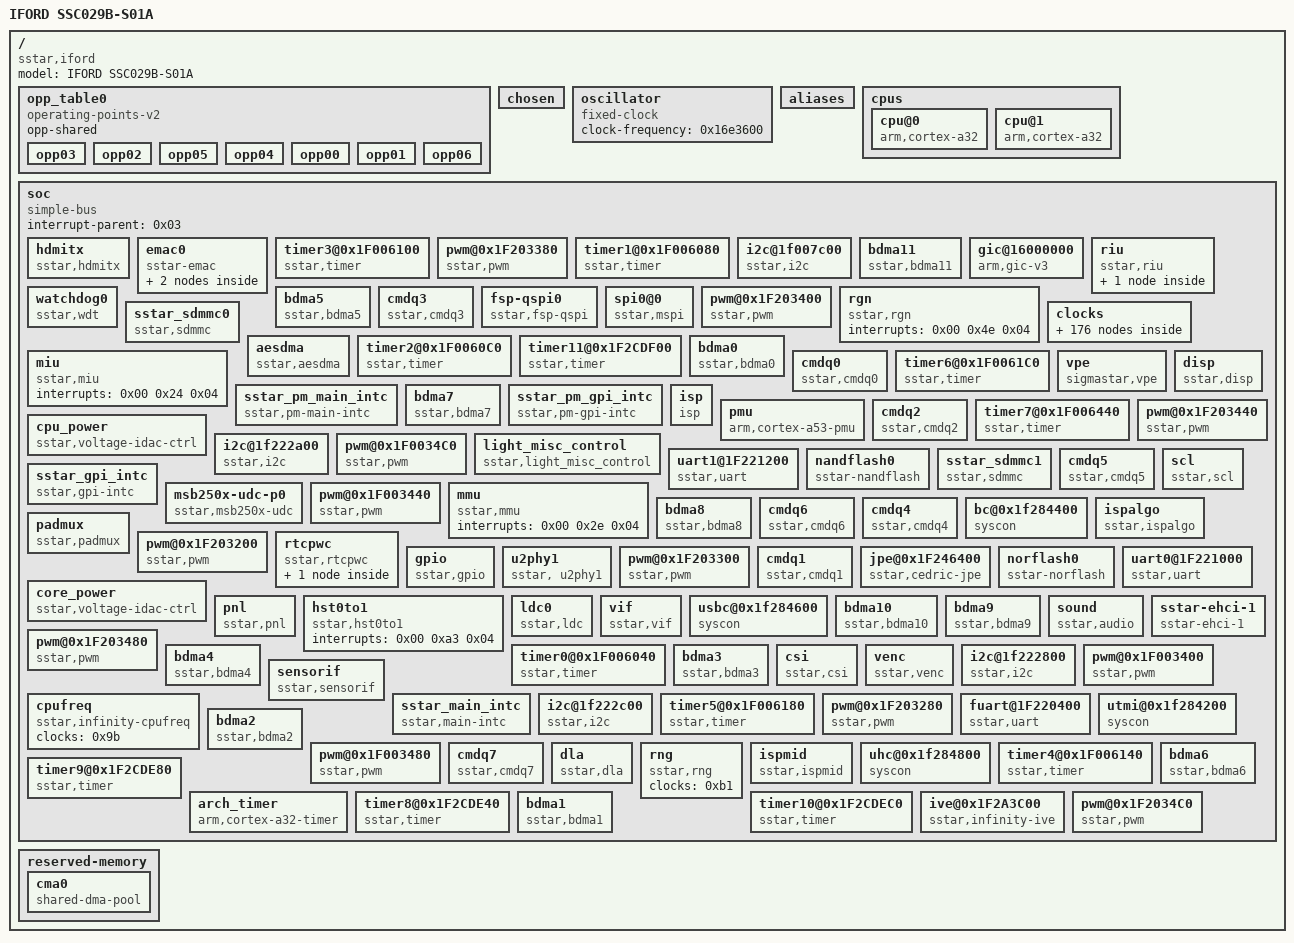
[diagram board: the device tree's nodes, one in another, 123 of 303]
/dts-v1/;

/ {
	model = "IFORD SSC029B-S01A";
	#address-cells = <0x01>;
	#size-cells = <0x01>;
	compatible = "sstar,iford";

	opp_table0 {
		opp-shared;
		phandle = <0x02>;
		compatible = "operating-points-v2";

		opp03 {
			status = "ok";
			opp-hz = <0x00 0x35a4e900>;
			opp-microvolt = <0xd6d80 0xcd140 0xd6d80>;
		};

		opp02 {
			status = "ok";
			opp-hz = <0x00 0x2faf0800>;
			opp-microvolt = <0xcf850 0xc5c10 0xcf850>;
		};

		opp05 {
			status = "ok";
			opp-hz = <0x00 0x4190ab00>;
			opp-microvolt = <0xe30d0 0xde2b0 0xe30d0>;
		};

		opp04 {
			status = "ok";
			opp-hz = <0x00 0x3b9aca00>;
			opp-microvolt = <0xdbba0 0xd4670 0xdbba0>;
		};

		opp00 {
			status = "ok";
			opp-hz = <0x00 0x23c34600>;
			opp-microvolt = <0xc3500 0xbbfd0 0xc3500>;
		};

		opp01 {
			status = "ok";
			opp-hz = <0x00 0x29b92700>;
			opp-microvolt = <0xc8320 0xc0df0 0xc8320>;
		};

		opp06 {
			status = "ok";
			opp-hz = <0x00 0x47868c00>;
			opp-microvolt = <0xecd10 0xe57e0 0xecd10>;
		};
	};

	chosen {
		bootargs = "console=ttyS0,115200n8r root=/dev/mtdblock3 ro init=/linuxrc LX_MEM=0x10000000 mma_heap=mma_heap_name0,miu=0,sz=0x8000000 mma_memblock_remove=1 cma=2M mtdparts=nor0:0x5F000(BOOT),0x1000(ENV),0x300000(KERNEL),0x220000(rootfs),0xB0000(MISC),0x4D0000(miservice),0x500000(customer) nohz=off";
	};

	oscillator {
		#clock-cells = <0x00>;
		phandle = <0xb2>;
		clock-frequency = <0x16e3600>;
		compatible = "fixed-clock";
	};

	__symbols__ {
		CLK_bist_vhe_gp = "/soc/clocks/CLK_bist_vhe_gp";
		CLK_bist_sc_gp = "/soc/clocks/CLK_bist_sc_gp";
		timer11 = "/soc/timer11@0x1F2CDF00";
		jpe0 = "/soc/jpe@0x1F246400";
		CLK_mpll_288m_div2 = "/soc/clocks/CLK_mpll_288m_div2";
		CLK_isp_p = "/soc/clocks/CLK_isp_p";
		CLK_mpll_432m_div16 = "/soc/clocks/CLK_mpll_432m_div16";
		CLK_pm_timer7 = "/soc/clocks/CLK_pm_timer7";
		hdmitx = "/soc/hdmitx";
		emac0 = "/soc/emac0";
		timer0 = "/soc/timer0@0x1F006040";
		CLK_fuart_synth_in = "/soc/clocks/CLK_fuart_synth_in";
		clks = "/soc/clocks";
		CLK_pm_sdio = "/soc/clocks/CLK_pm_sdio";
		CLK_sd = "/soc/clocks/CLK_sd";
		CLK_fclk1 = "/soc/clocks/CLK_fclk1";
		CLK_ipupll_clk = "/soc/clocks/CLK_ipupll_clk";
		CLK_sr02_mclk = "/soc/clocks/CLK_sr02_mclk";
		CLK_pm_high_ext = "/soc/clocks/CLK_pm_high_ext";
		CLK_ven_scdn = "/soc/clocks/CLK_ven_scdn";
		CLK_xtali_sc_gp = "/soc/clocks/CLK_xtali_sc_gp";
		CLK_miic2 = "/soc/clocks/CLK_miic2";
		CLK_riu_w_clk_mcu_if_gp = "/soc/clocks/CLK_riu_w_clk_mcu_if_gp";
		CLK_au_sys_432 = "/soc/clocks/CLK_au_sys_432";
		CLK_pm_timer6 = "/soc/clocks/CLK_pm_timer6";
		usb2phy1_uhc = "/soc/uhc@0x1f284800";
		CLK_xtali = "/soc/clocks/CLK_xtali";
		CLK_wdt = "/soc/clocks/CLK_wdt";
		phy0 = "/soc/emac0/mdio-bus@emac0/ethernet-phy@0";
		CLK_disppll_clk = "/soc/clocks/CLK_disppll_clk";
		timer7 = "/soc/timer7@0x1F006440";
		CLK_bist_ipu_gp = "/soc/clocks/CLK_bist_ipu_gp";
		CLK_pm_pspi0 = "/soc/clocks/CLK_pm_pspi0";
		ive0 = "/soc/ive@0x1F2A3C00";
		CLK_RTC_CLK_32K = "/soc/clocks/CLK_RTC_CLK_32K";
		xtal = "/oscillator";
		CLK_emac_ahb = "/soc/clocks/CLK_emac_ahb";
		rgn = "/soc/rgn";
		CLK_pm_timer5 = "/soc/clocks/CLK_pm_timer5";
		sstar_sdmmc0 = "/soc/sstar_sdmmc0";
		CLK_csi1_mac_top_i = "/soc/clocks/CLK_csi1_mac_top_i";
		CLK_bist = "/soc/clocks/CLK_bist";
		CLK_mpll_123m = "/soc/clocks/CLK_mpll_123m";
		usb2phy1_usbc = "/soc/usbc@0x1f284600";
		timer4 = "/soc/timer4@0x1F006140";
		CLK_source_mux_250m_div8 = "/soc/clocks/CLK_source_mux_250m_div8";
		CLK_riu_w_clk_sc_gp = "/soc/clocks/CLK_riu_w_clk_sc_gp";
		CLK_source_mux_250m_div5 = "/soc/clocks/CLK_source_mux_250m_div5";
		CLK_source_mux_250m = "/soc/clocks/CLK_source_mux_250m";
		CLK_mspi0 = "/soc/clocks/CLK_mspi0";
		CLK_12m_mux_div40 = "/soc/clocks/CLK_12m_mux_div40";
		CLK_fsp_qspi = "/soc/clocks/CLK_fsp_qspi";
		timer6 = "/soc/timer6@0x1F0061C0";
		CLK_pm_fuart1 = "/soc/clocks/CLK_pm_fuart1";
		CLK_VOID = "/soc/clocks/CLK_VOID";
		CLK_pm_uart0 = "/soc/clocks/CLK_pm_uart0";
		CLK_csi0_mac_lptx_top_i = "/soc/clocks/CLK_csi0_mac_lptx_top_i";
		vpe = "/soc/vpe";
		CLK_bist_miu0 = "/soc/clocks/CLK_bist_miu0";
		CLK_ven_sc_if = "/soc/clocks/CLK_ven_sc_if";
		disp = "/soc/disp";
		sstar_pm_main_intc = "/soc/sstar_pm_main_intc";
		CLK_fuart1_synth_in = "/soc/clocks/CLK_fuart1_synth_in";
		pwm0 = "/soc/pwm@0x1F203200";
		timer5 = "/soc/timer5@0x1F006180";
		CLK_pm_sleep = "/soc/clocks/CLK_pm_sleep";
		CLK_fclk1_p = "/soc/clocks/CLK_fclk1_p";
		CLK_fuart_synth_out = "/soc/clocks/CLK_fuart_synth_out";
		CLK_ddr_syn = "/soc/clocks/CLK_ddr_syn";
		CLK_mpll_288m_div4 = "/soc/clocks/CLK_mpll_288m_div4";
		CLK_pm_miic0 = "/soc/clocks/CLK_pm_miic0";
		pwm3 = "/soc/pwm@0x1F203380";
		CLK_riu_w_clk_top = "/soc/clocks/CLK_riu_w_clk_top";
		sstar_pm_gpi_intc = "/soc/sstar_pm_gpi_intc";
		CLK_mpll_432m = "/soc/clocks/CLK_mpll_432m";
		CLK_bist_pm_p = "/soc/clocks/CLK_bist_pm_p";
		CLK_source_mux_250m_div2 = "/soc/clocks/CLK_source_mux_250m_div2";
		isp = "/soc/isp";
		CLK_upll_320m_div16 = "/soc/clocks/CLK_upll_320m_div16";
		CLK_pm_sr_mclk = "/soc/clocks/CLK_pm_sr_mclk";
		pwm5 = "/soc/pwm@0x1F203440";
		CLK_upll_320m_div8 = "/soc/clocks/CLK_upll_320m_div8";
		usb2phy1_utmi = "/soc/utmi@0x1f284200";
		CLK_xtali_12m_div40 = "/soc/clocks/CLK_xtali_12m_div40";
		CLK_ive = "/soc/clocks/CLK_ive";
		CLK_riu_w_clk_mipi_if_gp = "/soc/clocks/CLK_riu_w_clk_mipi_if_gp";
		CLK_mcu_pm = "/soc/clocks/CLK_mcu_pm";
		CLK_disppll_clk_div2 = "/soc/clocks/CLK_disppll_clk_div2";
		CLK_mpll_86m_div16 = "/soc/clocks/CLK_mpll_86m_div16";
		timer8 = "/soc/timer8@0x1F2CDE40";
		CLK_pm_pwm = "/soc/clocks/CLK_pm_pwm";
		CLK_upll_480m = "/soc/clocks/CLK_upll_480m";
		sstar_u2phy1 = "/soc/u2phy1";
		uart1 = "/soc/uart1@1F221200";
		CLK_xtali_12m_div128 = "/soc/clocks/CLK_xtali_12m_div128";
		CLK_mpll_432m_div8 = "/soc/clocks/CLK_mpll_432m_div8";
		CLK_upll_320m_div2 = "/soc/clocks/CLK_upll_320m_div2";
		CLK_xtali_24m = "/soc/clocks/CLK_xtali_24m";
		CLK_xtali_12m_div16 = "/soc/clocks/CLK_xtali_12m_div16";
		CLK_pm_fuart0 = "/soc/clocks/CLK_pm_fuart0";
		CLK_otp = "/soc/clocks/CLK_otp";
		CLK_bist_mcu = "/soc/clocks/CLK_bist_mcu";
		CLK_fclk2_p = "/soc/clocks/CLK_fclk2_p";
		CLK_upll_320m_div10 = "/soc/clocks/CLK_upll_320m_div10";
		CLK_upll_480m_div2 = "/soc/clocks/CLK_upll_480m_div2";
		CLK_spi_synth_pll = "/soc/clocks/CLK_spi_synth_pll";
		sstar_sdmmc1 = "/soc/sstar_sdmmc1";
		CLK_pm_timer4 = "/soc/clocks/CLK_pm_timer4";
		CLK_sr00_mclk = "/soc/clocks/CLK_sr00_mclk";
		sstar_gpi_intc = "/soc/sstar_gpi_intc";
		CLK_ldcfeye = "/soc/clocks/CLK_ldcfeye";
		scl = "/soc/scl";
		CLK_riu_w_clk_in = "/soc/clocks/CLK_riu_w_clk_in";
		CLK_miu_rec = "/soc/clocks/CLK_miu_rec";
		CLK_csi0_ns_top_i = "/soc/clocks/CLK_csi0_ns_top_i";
		CLK_ir = "/soc/clocks/CLK_ir";
		CLK_xtali_12m_div8 = "/soc/clocks/CLK_xtali_12m_div8";
		CLK_aesdma = "/soc/clocks/CLK_aesdma";
		CLK_spi_nonpm = "/soc/clocks/CLK_spi_nonpm";
		CLK_mpll_123m_div2 = "/soc/clocks/CLK_mpll_123m_div2";
		CLK_mcu = "/soc/clocks/CLK_mcu";
		CLK_pwm = "/soc/clocks/CLK_pwm";
		CLK_fuart0_synth_out = "/soc/clocks/CLK_fuart0_synth_out";
		CLK_upll_384m_div2 = "/soc/clocks/CLK_upll_384m_div2";
		ispalgo = "/soc/ispalgo";
		CLK_mpll_86m = "/soc/clocks/CLK_mpll_86m";
		i2c1 = "/soc/i2c@1f222a00";
		CLK_miu_vhe_gp_p = "/soc/clocks/CLK_miu_vhe_gp_p";
		rtcpwc = "/soc/rtcpwc";
		CLK_mspi0_p = "/soc/clocks/CLK_mspi0_p";
		gpio = "/soc/gpio";
		CLK_emac_testrx125_in_lan = "/soc/clocks/CLK_emac_testrx125_in_lan";
		CLK_upll_320m = "/soc/clocks/CLK_upll_320m";
		CLK_CLK_12M_CORE_v_live = "/soc/clocks/CLK_CLK_12M_CORE_v_live";
		CLK_sr03_mclk = "/soc/clocks/CLK_sr03_mclk";
		CLK_fuart = "/soc/clocks/CLK_fuart";
		usb2phy1_bc = "/soc/bc@0x1f284400";
		CLK_mpll_86m_div4 = "/soc/clocks/CLK_mpll_86m_div4";
		CLK_csi0_mac_top_i = "/soc/clocks/CLK_csi0_mac_top_i";
		CLK_miu_isp_gp_p = "/soc/clocks/CLK_miu_isp_gp_p";
		pwm11 = "/soc/pwm@0x1F0034C0";
		CLK_bist_pm = "/soc/clocks/CLK_bist_pm";
		pnl = "/soc/pnl";
		CLK_riu_w_clk_hemcu_gp = "/soc/clocks/CLK_riu_w_clk_hemcu_gp";
		CLK_isp = "/soc/clocks/CLK_isp";
		CLK_rtc = "/soc/clocks/CLK_rtc";
		pwm2 = "/soc/pwm@0x1F203300";
		ldc0 = "/soc/ldc0";
		CLK_vif_pm = "/soc/clocks/CLK_vif_pm";
		i2c3 = "/soc/i2c@1f007c00";
		CLK_fuart0 = "/soc/clocks/CLK_fuart0";
		CLK_miu_sc_gp_p = "/soc/clocks/CLK_miu_sc_gp_p";
		vif = "/soc/vif";
		CLK_mpll_216m = "/soc/clocks/CLK_mpll_216m";
		CLK_pm_riu_w_clk_in = "/soc/clocks/CLK_pm_riu_w_clk_in";
		CLK_pir_pm = "/soc/clocks/CLK_pir_pm";
		i2c2 = "/soc/i2c@1f222c00";
		CLK_fuart1_synth_out = "/soc/clocks/CLK_fuart1_synth_out";
		CLK_ipuff = "/soc/clocks/CLK_ipuff";
		pwm8 = "/soc/pwm@0x1F003400";
		CLK_ipu = "/soc/clocks/CLK_ipu";
		CLK_real_live = "/soc/clocks/CLK_real_live";
		CLK_miu_boot = "/soc/clocks/CLK_miu_boot";
		CLK_cpu_pll = "/soc/clocks/CLK_cpu_pll";
		CLK_csi1_mac_lptx_top_i = "/soc/clocks/CLK_csi1_mac_lptx_top_i";
		timer10 = "/soc/timer10@0x1F2CDEC0";
		pwm4 = "/soc/pwm@0x1F203400";
		CLK_12m_mux = "/soc/clocks/CLK_12m_mux";
		csi = "/soc/csi";
		CLK_sr01_mclk = "/soc/clocks/CLK_sr01_mclk";
		CLK_miic0 = "/soc/clocks/CLK_miic0";
		pwm7 = "/soc/pwm@0x1F2034C0";
		CLK_mpll_288m_div8 = "/soc/clocks/CLK_mpll_288m_div8";
		CLK_upll_960m = "/soc/clocks/CLK_upll_960m";
		CLK_jpe = "/soc/clocks/CLK_jpe";
		CLK_sar = "/soc/clocks/CLK_sar";
		CLK_ssi_dphy = "/soc/clocks/CLK_ssi_dphy";
		sensorif = "/soc/sensorif";
		timer9 = "/soc/timer9@0x1F2CDE80";
		uart0 = "/soc/uart0@1F221000";
		CLK_sr_mclk = "/soc/clocks/CLK_sr_mclk";
		CLK_upll_384m = "/soc/clocks/CLK_upll_384m";
		CLK_ven_axi = "/soc/clocks/CLK_ven_axi";
		sstar_main_intc = "/soc/sstar_main_intc";
		CLK_csi1_ns_top_i = "/soc/clocks/CLK_csi1_ns_top_i";
		CLK_disp_pixel_0 = "/soc/clocks/CLK_disp_pixel_0";
		CLK_upll_48m = "/soc/clocks/CLK_upll_48m";
		CLK_xtali_12m_div64 = "/soc/clocks/CLK_xtali_12m_div64";
		CLK_live = "/soc/clocks/CLK_live";
		i2c0 = "/soc/i2c@1f222800";
		CLK_pad_test = "/soc/clocks/CLK_pad_test";
		CLK_miu_p = "/soc/clocks/CLK_miu_p";
		CLK_armpll_37p125m = "/soc/clocks/CLK_armpll_37p125m";
		CLK_bist_isp_gp = "/soc/clocks/CLK_bist_isp_gp";
		pwm6 = "/soc/pwm@0x1F203480";
		CLK_riubrdg = "/soc/clocks/CLK_riubrdg";
		CLK_hemcu = "/soc/clocks/CLK_hemcu";
		gic = "/soc/gic@16000000";
		CLK_mcu_pm_p = "/soc/clocks/CLK_mcu_pm_p";
		CLK_source_mux_250m_div4 = "/soc/clocks/CLK_source_mux_250m_div4";
		CLK_au_sys_384 = "/soc/clocks/CLK_au_sys_384";
		CLK_rtcpll_clk = "/soc/clocks/CLK_rtcpll_clk";
		CLK_riu_w_clk_vhe_gp = "/soc/clocks/CLK_riu_w_clk_vhe_gp";
		CLK_mpll_172m = "/soc/clocks/CLK_mpll_172m";
		ispmid = "/soc/ispmid";
		CLK_live_c = "/soc/clocks/CLK_live_c";
		CLK_wdma = "/soc/clocks/CLK_wdma";
		CLK_upll_384m_div8 = "/soc/clocks/CLK_upll_384m_div8";
		CLK_mpll_288m = "/soc/clocks/CLK_mpll_288m";
		CLK_mpll_86m_div2 = "/soc/clocks/CLK_mpll_86m_div2";
		CLK_mcu_p = "/soc/clocks/CLK_mcu_p";
		CLK_mpll_345m = "/soc/clocks/CLK_mpll_345m";
		cpu0_opp_table = "/opp_table0";
		usclk = "/soc/clocks/usclk";
		fuart = "/soc/fuart@1F220400";
		timer1 = "/soc/timer1@0x1F006080";
		timer2 = "/soc/timer2@0x1F0060C0";
		timer3 = "/soc/timer3@0x1F006100";
		CLK_mfe = "/soc/clocks/CLK_mfe";
		CLK_vhe = "/soc/clocks/CLK_vhe";
		CLK_odclk = "/soc/clocks/CLK_odclk";
		CLK_xtali_12m_div4 = "/soc/clocks/CLK_xtali_12m_div4";
		CLK_12m_mux_div2 = "/soc/clocks/CLK_12m_mux_div2";
		CLK_mpll_432m_div4 = "/soc/clocks/CLK_mpll_432m_div4";
		CLK_dsc_enc1 = "/soc/clocks/CLK_dsc_enc1";
		CLK_24m_mux = "/soc/clocks/CLK_24m_mux";
		CLK_xtali_12m = "/soc/clocks/CLK_xtali_12m";
		CLK_pwr_ctl = "/soc/clocks/CLK_pwr_ctl";
		CLK_xtali_12m_div2 = "/soc/clocks/CLK_xtali_12m_div2";
		CLK_fuart1 = "/soc/clocks/CLK_fuart1";
		CLK_dsc_dec1 = "/soc/clocks/CLK_dsc_dec1";
		CLK_miu2x_p = "/soc/clocks/CLK_miu2x_p";
		pwm1 = "/soc/pwm@0x1F203280";
		pwm9 = "/soc/pwm@0x1F003440";
		CLK_fuart0_synth_in = "/soc/clocks/CLK_fuart0_synth_in";
		CLK_source_mux_250m_div6 = "/soc/clocks/CLK_source_mux_250m_div6";
		pwm10 = "/soc/pwm@0x1F003480";
		CLK_pm_pwr_ctl = "/soc/clocks/CLK_pm_pwr_ctl";
		CLK_miic1 = "/soc/clocks/CLK_miic1";
		CLK_miupll_clk = "/soc/clocks/CLK_miupll_clk";
		CLK_otp_p = "/soc/clocks/CLK_otp_p";
	};

	aliases {
		sdmmc1 = "/soc/sstar_sdmmc1";
		serial0 = "/soc/uart0@1F221000";
		console = "/soc/uart0@1F221000";
		serial2 = "/soc/fuart@1F220400";
		sdmmc0 = "/soc/sstar_sdmmc0";
		serial1 = "/soc/uart1@1F221200";
	};

	cpus {
		#address-cells = <0x01>;
		#size-cells = <0x00>;

		cpu@0 {
			clocks = <0x01>;
			reg = <0x00>;
			clock-frequency = <0x3b9aca00>;
			operating-points-v2 = <0x02>;
			device_type = "cpu";
			compatible = "arm,cortex-a32";
		};

		cpu@1 {
			clocks = <0x01>;
			reg = <0x01>;
			clock-frequency = <0x3b9aca00>;
			device_type = "cpu";
			compatible = "arm,cortex-a32";
		};
	};

	soc {
		interrupt-parent = <0x03>;
		#address-cells = <0x01>;
		ranges;
		#size-cells = <0x01>;
		compatible = "simple-bus";

		hdmitx {
			status = "ok";
			phandle = <0xdc>;
			compatible = "sstar,hdmitx";
		};

		emac0 {
			clocks = <0x62>;
			pad = <0x1f203c38 0x01 0x01>;
			status = "ok";
			interrupts = <0x00 0x33 0x04 0x00 0xb5 0x04 0x00 0x4c 0x04>;
			phandle = <0xc3>;
			reg = <0x1f2a2000 0x800 0x1f304200 0x600 0x1f2a3000 0x600>;
			bus-mode = <0x01>;
			phy-handle = <0xb4>;
			compatible = "sstar-emac";

			mdio-bus@emac0 {

				ethernet-phy@0 {
					phandle = <0xb4>;
					phy-mode = "mii";
				};
			};
		};

		timer3@0x1F006100 {
			clocks = <0x73>;
			status = "ok";
			interrupts = <0x00 0xa0 0x04>;
			phandle = <0xc9>;
			reg = <0x1f006100 0x40>;
			compatible = "sstar,timer";
		};

		pwm@0x1F203380 {
			clocks = <0x8e>;
			channel = <0x03>;
			status = "ok";
			interrupts = <0x00 0x5b 0x04>;
			phandle = <0xe3>;
			reg = <0x1f203380 0x37>;
			group = <0x00>;
			#pwm-cells = <0x03>;
			clk-select = <0x00>;
			compatible = "sstar,pwm";
		};

		timer1@0x1F006080 {
			clocks = <0x73>;
			status = "ok";
			interrupts = <0x00 0xa0 0x04>;
			phandle = <0xc7>;
			reg = <0x1f006080 0x40>;
			compatible = "sstar,timer";
		};

		i2c@1f007c00 {
			t-hd-sto = <0x00>;
			t-hd-sta = <0x00>;
			output-mode = <0x02>;
			clocks = <0x85>;
			status = "ok";
			interrupts = <0x00 0x2b 0x04>;
			phandle = <0xf1>;
			t-su-sta = <0x00>;
			reg = <0x1f007c00 0x200>;
			t-su-sto = <0x00>;
			#address-cells = <0x01>;
			#size-cells = <0x00>;
			group = <0x03>;
			speed = <0x30d40>;
			compatible = "sstar,i2c";
			dma-enable;
		};

		bdma11 {
			clocks = <0xb2>;
			status = "ok";
			interrupts = <0x00 0x4b 0x04>;
			reg = <0x1f008b80 0x80>;
			compatible = "sstar,bdma11";
		};

		gic@16000000 {
			interrupt-parent = <0x04>;
			phandle = <0x04>;
			#interrupt-cells = <0x03>;
			reg = <0x16000000 0x20000 0x16040000 0x80000>;
			redistributor-stride = <0x00 0x20000>;
			interrupt-controller;
			#address-cells = <0x01>;
			#redistributor-regions = <0x01>;
			#size-cells = <0x01>;
			compatible = "arm,gic-v3";
		};

		riu {
			status = "ok";
			#address-cells = <0x01>;
			ranges;
			#size-cells = <0x01>;
			compatible = "sstar,riu";

			timeout {
				status = "ok";
				interrupts = <0x00 0xa4 0x04 0x00 0xb6 0x04 0x00 0xb4 0x04>;
				reg = <0x1f000200 0x200 0x1f200200 0x200 0x1f2ce000 0x200>;
				print-on;
			};
		};

		watchdog0 {
			clocks = <0xa8>;
			status = "ok";
			interrupts = <0x00 0xa1 0x04>;
			reg = <0x1f006000 0x40>;
			compatible = "sstar,wdt";
		};

		bdma5 {
			clocks = <0xb2>;
			status = "ok";
			interrupts = <0x00 0x49 0x04>;
			reg = <0x1f201680 0x80>;
			compatible = "sstar,bdma5";
		};

		cmdq3 {
			clocks = <0x10>;
			status = "ok";
			interrupts = <0x00 0x31 0x04>;
			compatible = "sstar,cmdq3";
		};

		fsp-qspi0 {
			dma = <0x01>;
			clocks = <0xb3 0x29>;
			cs-mode = <0x00>;
			status = "ok";
			cs-num = <0x02>;
			engine = <0x00>;
			reg = <0x1f201a00 0x200 0x1f201c00 0x200>;
			compatible = "sstar,fsp-qspi";
		};

		spi0@0 {
			clocks = <0x15>;
			status = "ok";
			cs-num = <0x01>;
			interrupts = <0x00 0x46 0x04>;
			reg = <0x1f222000 0x200>;
			mspi-group = <0x00>;
			compatible = "sstar,mspi";
			dma-enable;
		};

		pwm@0x1F203400 {
			clocks = <0x8e>;
			channel = <0x04>;
			status = "ok";
			interrupts = <0x00 0x5b 0x04>;
			phandle = <0xe4>;
			reg = <0x1f203400 0x37>;
			group = <0x01>;
			#pwm-cells = <0x03>;
			clk-select = <0x00>;
			compatible = "sstar,pwm";
		};

		rgn {
			status = "ok";
			interrupts = <0x00 0x4e 0x04>;
			phandle = <0xed>;
			compatible = "sstar,rgn";
		};

		clocks {
			phandle = <0xbd>;
			#address-cells = <0x01>;
			ranges;
			#size-cells = <0x01>;

			CLK_bist_vhe_gp {
				#clock-cells = <0x00>;
				clocks = <0x1b 0x0c 0x25 0x0f>;
				auto-enable = <0x00>;
				phandle = <0x57>;
				reg = <0x1f20700c 0x04>;
				mux-width = <0x02>;
				mux-shift = <0x0a>;
				compatible = "sstar,composite-clock";
				gate-shift = <0x08>;
			};

			CLK_bist_sc_gp {
				#clock-cells = <0x00>;
				clocks = <0x1b 0x0c 0x25 0x0f>;
				auto-enable = <0x00>;
				phandle = <0x56>;
				reg = <0x1f20700c 0x04>;
				mux-width = <0x02>;
				mux-shift = <0x02>;
				compatible = "sstar,composite-clock";
				gate-shift = <0x00>;
			};

			CLK_mpll_288m_div2 {
				#clock-cells = <0x00>;
				clock-div = <0x02>;
				clocks = <0x0a>;
				phandle = <0x25>;
				clock-mult = <0x01>;
				compatible = "fixed-factor-clock";
			};

			CLK_isp_p {
				#clock-cells = <0x00>;
				clock-div = <0x01>;
				clocks = <0x17>;
				phandle = <0x6d>;
				clock-mult = <0x01>;
				compatible = "fixed-factor-clock";
			};

			CLK_mpll_432m_div16 {
				#clock-cells = <0x00>;
				clock-div = <0x10>;
				clocks = <0x0b>;
				phandle = <0x2d>;
				clock-mult = <0x01>;
				compatible = "fixed-factor-clock";
			};

			CLK_pm_timer7 {
				#clock-cells = <0x00>;
				clocks = <0x1a>;
				phandle = <0xae>;
				clock-frequency = <0xb71b00>;
				compatible = "sstar,complex-clock";
			};

			CLK_fuart_synth_in {
				#clock-cells = <0x00>;
				clocks = <0x0b 0x1b>;
				auto-enable = <0x00>;
				phandle = <0x11>;
				reg = <0x1f2070d0 0x04>;
				mux-width = <0x02>;
				mux-shift = <0x06>;
				compatible = "sstar,composite-clock";
				gate-shift = <0x04>;
			};

			CLK_pm_sdio {
				#clock-cells = <0x00>;
				clocks = <0x44 0x46 0x47 0x19 0x0f>;
				glitch-shift = <0x0f>;
				phandle = <0x8a>;
				reg = <0x1f001c90 0x04>;
				ignore = <0x01>;
				mux-width = <0x02>;
				mux-shift = <0x0d>;
				compatible = "sstar,composite-clock";
				gate-shift = <0x0b>;
			};

			CLK_sd {
				#clock-cells = <0x00>;
				clocks = <0x2f 0x30 0x38 0x31 0x39 0x3a 0x0f 0x3b 0x29 0x0b 0x08 0x09 0x0a 0x1b 0x20 0x0d 0x0f>;
				glitch-shift = <0x06>;
				auto-enable = <0x00>;
				phandle = <0x9c>;
				reg = <0x1f20710c 0x04>;
				mux-width = <0x04>;
				mux-shift = <0x02>;
				compatible = "sstar,composite-clock";
				gate-shift = <0x00>;
			};

			CLK_fclk1 {
				#clock-cells = <0x00>;
				clocks = <0x0a 0x2c 0x25 0x09 0x35 0x1b>;
				dfs-width = <0x05>;
				nonod-shift = <0x00>;
				auto-enable = <0x00>;
				phandle = <0x18>;
				reg = <0x1f207190 0x04 0x1f2071d8 0x04>;
				mux-width = <0x03>;
				mux-shift = <0x02>;
				compatible = "sstar,composite-clock";
				dfs-shift = <0x00>;
				gate-shift = <0x00>;
				od-shift = <0x03>;
			};

			CLK_ipupll_clk {
				#clock-cells = <0x00>;
				clocks = <0x0b>;
				phandle = <0x6b>;
				compatible = "sstar,complex-clock";
			};

			CLK_sr02_mclk {
				#clock-cells = <0x00>;
				clocks = <0x2d 0x2a 0x2e 0x2b 0x2f 0x30 0x31 0x05 0x32 0x0f 0x33 0x34>;
				dfs-width = <0x05>;
				auto-enable = <0x00>;
				phandle = <0x9f>;
				reg = <0x1f207194 0x04 0x1f2071e0 0x04>;
				mux-width = <0x04>;
				mux-shift = <0x0a>;
				compatible = "sstar,composite-clock";
				dfs-shift = <0x08>;
				gate-shift = <0x08>;
			};

			CLK_pm_high_ext {
				#clock-cells = <0x00>;
				clocks = <0x35 0x1b 0x2c 0x41>;
				phandle = <0x84>;
				reg = <0x1f207040 0x04>;
				ignore = <0x01>;
				mux-width = <0x02>;
				mux-shift = <0x02>;
				compatible = "sstar,composite-clock";
				gate-shift = <0x00>;
			};

			CLK_ven_scdn {
				#clock-cells = <0x00>;
				clocks = <0x1b 0x35 0x36 0x08 0x0b 0x07 0x0a 0x2c>;
				dfs-width = <0x05>;
				nonod-shift = <0x02>;
				auto-enable = <0x00>;
				phandle = <0xa5>;
				reg = <0x1f207fe4 0x04 0x1f207fe0 0x04>;
				mux-width = <0x03>;
				mux-shift = <0x02>;
				compatible = "sstar,composite-clock";
				dfs-shift = <0x00>;
				gate-shift = <0x00>;
				od-shift = <0x04>;
			};

			CLK_xtali_sc_gp {
				#clock-cells = <0x00>;
				clocks = <0x0f>;
				auto-enable = <0x01>;
				phandle = <0xaa>;
				reg = <0x1f207000 0x04>;
				mux-width = <0x02>;
				mux-shift = <0x06>;
				compatible = "sstar,composite-clock";
				gate-shift = <0x04>;
			};

			CLK_miic2 {
				#clock-cells = <0x00>;
				clocks = <0x2a 0x2b 0x0f>;
				auto-enable = <0x00>;
				phandle = <0x77>;
				reg = <0x1f2070dc 0x04>;
				mux-width = <0x02>;
				mux-shift = <0x0e>;
				compatible = "sstar,composite-clock";
				gate-shift = <0x0c>;
			};

			CLK_riu_w_clk_mcu_if_gp {
				#clock-cells = <0x00>;
				clock-div = <0x01>;
				clocks = <0x10>;
				phandle = <0x93>;
				clock-mult = <0x01>;
				compatible = "fixed-factor-clock";
			};

			CLK_au_sys_432 {
				#clock-cells = <0x00>;
				clocks = <0x0b 0x07 0x08>;
				auto-enable = <0x00>;
				phandle = <0x4f>;
				reg = <0x1f207fa4 0x04>;
				mux-width = <0x02>;
				mux-shift = <0x02>;
				compatible = "sstar,composite-clock";
				gate-shift = <0x00>;
			};

			CLK_pm_timer6 {
				#clock-cells = <0x00>;
				clocks = <0x1a>;
				phandle = <0xad>;
				clock-frequency = <0xb71b00>;
				compatible = "sstar,complex-clock";
			};

			CLK_xtali {
				#clock-cells = <0x00>;
				clocks = <0x0f>;
				auto-enable = <0x01>;
				phandle = <0xa9>;
				reg = <0x1f207000 0x04>;
				mux-width = <0x02>;
				mux-shift = <0x02>;
				compatible = "sstar,composite-clock";
				gate-shift = <0x00>;
			};

			CLK_wdt {
				#clock-cells = <0x00>;
				clocks = <0x42>;
				glitch-shift = <0x08>;
				phandle = <0xa8>;
				reg = <0x1f001c8c 0x04>;
				ignore = <0x01>;
				mux-width = <0x02>;
				mux-shift = <0x06>;
				compatible = "sstar,composite-clock";
				gate-shift = <0x04>;
			};

			CLK_disppll_clk {
				#clock-cells = <0x00>;
				clocks = <0x0b>;
				phandle = <0x0e>;
				compatible = "sstar,complex-clock";
			};

			CLK_bist_ipu_gp {
				#clock-cells = <0x00>;
				clocks = <0x1b 0x0c 0x25 0x0f>;
				auto-enable = <0x00>;
				phandle = <0x51>;
				reg = <0x1f207014 0x04>;
				mux-width = <0x02>;
				mux-shift = <0x02>;
				compatible = "sstar,composite-clock";
				gate-shift = <0x00>;
			};

			CLK_pm_pspi0 {
				#clock-cells = <0x00>;
				clocks = <0x43 0x42 0x1a 0x44>;
				phandle = <0x86>;
				reg = <0x1f001c84 0x04>;
				ignore = <0x01>;
				mux-width = <0x02>;
				mux-shift = <0x0c>;
				compatible = "sstar,composite-clock";
				gate-shift = <0x0a>;
			};

			CLK_RTC_CLK_32K {
				#clock-cells = <0x00>;
				phandle = <0x4b>;
				clock-frequency = <0x7d00>;
				compatible = "fixed-clock";
			};

			CLK_emac_ahb {
				#clock-cells = <0x00>;
				clocks = <0x25 0x0c 0x0d 0x3f>;
				auto-enable = <0x01>;
				phandle = <0x62>;
				reg = <0x1f207108 0x04>;
				mux-width = <0x02>;
				mux-shift = <0x02>;
				compatible = "sstar,composite-clock";
				gate-shift = <0x00>;
			};

			CLK_pm_timer5 {
				#clock-cells = <0x00>;
				clocks = <0x1a>;
				phandle = <0xac>;
				clock-frequency = <0xb71b00>;
				compatible = "sstar,complex-clock";
			};

			CLK_csi1_mac_top_i {
				#clock-cells = <0x00>;
				clocks = <0x0b 0x0a 0x09 0x24>;
				dfs-width = <0x05>;
				auto-enable = <0x00>;
				phandle = <0x5c>;
				reg = <0x1f207168 0x04 0x1f2071f4 0x04>;
				mux-width = <0x02>;
				mux-shift = <0x02>;
				compatible = "sstar,composite-clock";
				dfs-shift = <0x08>;
				gate-shift = <0x00>;
			};

			CLK_bist {
				#clock-cells = <0x00>;
				clocks = <0x1b 0x0c 0x25 0x0f>;
				auto-enable = <0x00>;
				phandle = <0x50>;
				reg = <0x1f207008 0x04>;
				mux-width = <0x02>;
				mux-shift = <0x0e>;
				compatible = "sstar,composite-clock";
				gate-shift = <0x0c>;
			};

			CLK_mpll_123m {
				#clock-cells = <0x00>;
				phandle = <0x0c>;
				clock-frequency = <0x75aef40>;
				compatible = "fixed-clock";
			};

			CLK_source_mux_250m_div8 {
				#clock-cells = <0x00>;
				clock-div = <0x08>;
				clocks = <0x19>;
				phandle = <0x48>;
				clock-mult = <0x01>;
				compatible = "fixed-factor-clock";
			};

			CLK_riu_w_clk_sc_gp {
				#clock-cells = <0x00>;
				clock-div = <0x01>;
				clocks = <0x10>;
				phandle = <0x95>;
				clock-mult = <0x01>;
				compatible = "fixed-factor-clock";
			};

			CLK_source_mux_250m_div5 {
				#clock-cells = <0x00>;
				clock-div = <0x05>;
				clocks = <0x19>;
				phandle = <0x45>;
				clock-mult = <0x01>;
				compatible = "fixed-factor-clock";
			};

			CLK_source_mux_250m {
				#clock-cells = <0x00>;
				phandle = <0x19>;
				clock-frequency = <0xbebc200>;
				compatible = "fixed-clock";
			};

			CLK_mspi0 {
				#clock-cells = <0x00>;
				clocks = <0x20 0x25 0x0f 0x29>;
				auto-enable = <0x00>;
				phandle = <0x15>;
				reg = <0x1f2070cc 0x04>;
				mux-width = <0x02>;
				mux-shift = <0x02>;
				compatible = "sstar,composite-clock";
				gate-shift = <0x00>;
			};

			CLK_12m_mux_div40 {
				#clock-cells = <0x00>;
				clock-div = <0x28>;
				clocks = <0x1a>;
				phandle = <0x47>;
				clock-mult = <0x01>;
				compatible = "fixed-factor-clock";
			};

			CLK_fsp_qspi {
				#clock-cells = <0x00>;
				clocks = <0x3c 0x29>;
				glitch-shift = <0x04>;
				auto-enable = <0x00>;
				phandle = <0xb3>;
				reg = <0x1f202aa8 0x04>;
				mux-width = <0x02>;
				mux-shift = <0x02>;
				compatible = "sstar,composite-clock";
				gate-shift = <0x00>;
			};

			CLK_pm_fuart1 {
				#clock-cells = <0x00>;
				clocks = <0x42>;
				phandle = <0x83>;
				reg = <0x1f001d08 0x04>;
				ignore = <0x01>;
				mux-width = <0x02>;
				mux-shift = <0x0e>;
				compatible = "sstar,composite-clock";
				gate-shift = <0x0c>;
			};

			CLK_VOID {
				#clock-cells = <0x00>;
				phandle = <0x4c>;
				clock-frequency = <0x01>;
				compatible = "fixed-clock";
			};

			CLK_pm_uart0 {
				#clock-cells = <0x00>;
				clocks = <0x42>;
				phandle = <0x8d>;
				reg = <0x1f001c94 0x04>;
				ignore = <0x01>;
				mux-width = <0x02>;
				mux-shift = <0x02>;
				compatible = "sstar,composite-clock";
				gate-shift = <0x00>;
			};

			CLK_csi0_mac_lptx_top_i {
				#clock-cells = <0x00>;
				clocks = <0x0b 0x0a 0x09 0x24>;
				dfs-width = <0x05>;
				auto-enable = <0x00>;
				phandle = <0x58>;
				reg = <0x1f207160 0x04 0x1f2071e8 0x04>;
				mux-width = <0x02>;
				mux-shift = <0x02>;
				compatible = "sstar,composite-clock";
				dfs-shift = <0x08>;
				gate-shift = <0x00>;
			};

			CLK_bist_miu0 {
				#clock-cells = <0x00>;
				clocks = <0x1b 0x0c 0x25 0x0f>;
				auto-enable = <0x00>;
				phandle = <0x54>;
				reg = <0x1f207e2c 0x04>;
				mux-width = <0x02>;
				mux-shift = <0x02>;
				compatible = "sstar,composite-clock";
				gate-shift = <0x00>;
			};

			CLK_ven_sc_if {
				#clock-cells = <0x00>;
				clocks = <0x20 0x0c 0x1b 0x0d>;
				dfs-width = <0x05>;
				auto-enable = <0x00>;
				phandle = <0xa4>;
				reg = <0x1f207e48 0x04 0x1f207ee8 0x04>;
				mux-width = <0x02>;
				mux-shift = <0x0a>;
				compatible = "sstar,composite-clock";
				dfs-shift = <0x08>;
				gate-shift = <0x08>;
			};

			CLK_fuart1_synth_in {
				#clock-cells = <0x00>;
				clocks = <0x0b 0x1b>;
				auto-enable = <0x00>;
				phandle = <0x13>;
				reg = <0x1f2070e8 0x04>;
				mux-width = <0x02>;
				mux-shift = <0x06>;
				compatible = "sstar,composite-clock";
				gate-shift = <0x04>;
			};

			CLK_pm_sleep {
				#clock-cells = <0x00>;
				clocks = <0x1a>;
				phandle = <0x8b>;
				reg = <0x1f001c88 0x04>;
				ignore = <0x01>;
				mux-width = <0x02>;
				mux-shift = <0x0c>;
				compatible = "sstar,composite-clock";
				gate-shift = <0x0a>;
			};

			CLK_fclk1_p {
				#clock-cells = <0x00>;
				clock-div = <0x01>;
				clocks = <0x18>;
				phandle = <0x63>;
				clock-mult = <0x01>;
				compatible = "fixed-factor-clock";
			};

			CLK_fuart_synth_out {
				#clock-cells = <0x00>;
				clocks = <0x11>;
				phandle = <0x26>;
				compatible = "sstar,complex-clock";
			};

			CLK_ddr_syn {
				#clock-cells = <0x00>;
				clocks = <0x0b 0x1b 0x0f>;
				auto-enable = <0x01>;
				phandle = <0x5e>;
				reg = <0x1f207064 0x04>;
				mux-width = <0x02>;
				mux-shift = <0x02>;
				compatible = "sstar,composite-clock";
				gate-shift = <0x00>;
			};

			CLK_mpll_288m_div4 {
				#clock-cells = <0x00>;
				clock-div = <0x04>;
				clocks = <0x0a>;
				phandle = <0x2a>;
				clock-mult = <0x01>;
				compatible = "fixed-factor-clock";
			};

			CLK_pm_miic0 {
				#clock-cells = <0x00>;
				clocks = <0x42>;
				auto-enable = <0x00>;
				phandle = <0x85>;
				reg = <0x1f001c98 0x04>;
				mux-width = <0x02>;
				mux-shift = <0x02>;
				compatible = "sstar,composite-clock";
				gate-shift = <0x00>;
			};

			CLK_riu_w_clk_top {
				#clock-cells = <0x00>;
				clock-div = <0x01>;
				clocks = <0x10>;
				phandle = <0x96>;
				clock-mult = <0x01>;
				compatible = "fixed-factor-clock";
			};

			CLK_mpll_432m {
				#clock-cells = <0x00>;
				phandle = <0x0b>;
				clock-frequency = <0x19bfcc00>;
				compatible = "fixed-clock";
			};

			CLK_bist_pm_p {
				#clock-cells = <0x00>;
				phandle = <0x41>;
				clock-frequency = <0xb71b000>;
				compatible = "fixed-clock";
			};

			CLK_source_mux_250m_div2 {
				#clock-cells = <0x00>;
				clock-div = <0x02>;
				clocks = <0x19>;
				phandle = <0x43>;
				clock-mult = <0x01>;
				compatible = "fixed-factor-clock";
			};

			CLK_upll_320m_div16 {
				#clock-cells = <0x00>;
				clock-div = <0x10>;
				clocks = <0x09>;
				phandle = <0x3a>;
				clock-mult = <0x01>;
				compatible = "fixed-factor-clock";
			};

			CLK_pm_sr_mclk {
				#clock-cells = <0x00>;
				clocks = <0x48 0x42 0x1a 0x49>;
				phandle = <0x8c>;
				reg = <0x1f001d14 0x04>;
				ignore = <0x01>;
				mux-width = <0x02>;
				mux-shift = <0x0a>;
				compatible = "sstar,composite-clock";
				gate-shift = <0x08>;
			};

			CLK_upll_320m_div8 {
				#clock-cells = <0x00>;
				clock-div = <0x08>;
				clocks = <0x09>;
				phandle = <0x38>;
				clock-mult = <0x01>;
				compatible = "fixed-factor-clock";
			};

			CLK_xtali_12m_div40 {
				#clock-cells = <0x00>;
				clock-div = <0x28>;
				clocks = <0x0f>;
				phandle = <0x3b>;
				clock-mult = <0x01>;
				compatible = "fixed-factor-clock";
			};

			CLK_ive {
				#clock-cells = <0x00>;
				clocks = <0x0a 0x1b 0x08 0x0b>;
				dfs-width = <0x05>;
				nonod-shift = <0x02>;
				auto-enable = <0x00>;
				phandle = <0x6e>;
				reg = <0x1f2071a8 0x04 0x1f2071e4 0x04>;
				mux-width = <0x02>;
				mux-shift = <0x0a>;
				compatible = "sstar,composite-clock";
				dfs-shift = <0x00>;
				gate-shift = <0x08>;
				od-shift = <0x03>;
			};

			CLK_riu_w_clk_mipi_if_gp {
				#clock-cells = <0x00>;
				clock-div = <0x01>;
				clocks = <0x10>;
				phandle = <0x94>;
				clock-mult = <0x01>;
				compatible = "fixed-factor-clock";
			};

			CLK_mcu_pm {
				#clock-cells = <0x00>;
				clocks = <0x19 0x42 0x45 0x43 0x0f>;
				glitch-shift = <0x04>;
				auto-enable = <0x01>;
				phandle = <0x16>;
				str-ignore;
				reg = <0x1f001c80 0x04>;
				mux-width = <0x02>;
				mux-shift = <0x02>;
				compatible = "sstar,composite-clock";
				gate-shift = <0x00>;
			};

			CLK_disppll_clk_div2 {
				#clock-cells = <0x00>;
				clock-div = <0x02>;
				clocks = <0x0e>;
				phandle = <0x3e>;
				clock-mult = <0x01>;
				compatible = "fixed-factor-clock";
			};

			CLK_mpll_86m_div16 {
				#clock-cells = <0x00>;
				clock-div = <0x10>;
				clocks = <0x0d>;
				phandle = <0x33>;
				clock-mult = <0x01>;
				compatible = "fixed-factor-clock";
			};

			CLK_pm_pwm {
				#clock-cells = <0x00>;
				clocks = <0x1a>;
				phandle = <0x87>;
				reg = <0x1f001c70 0x04>;
				ignore = <0x01>;
				mux-width = <0x02>;
				mux-shift = <0x0c>;
				compatible = "sstar,composite-clock";
				gate-shift = <0x0a>;
			};

			CLK_upll_480m {
				#clock-cells = <0x00>;
				clocks = <0x06>;
				phandle = <0x07>;
				compatible = "sstar,complex-clock";
			};

			CLK_xtali_12m_div128 {
				#clock-cells = <0x00>;
				clock-div = <0x80>;
				clocks = <0x0f>;
				phandle = <0x1f>;
				clock-mult = <0x01>;
				compatible = "fixed-factor-clock";
			};

			CLK_mpll_432m_div8 {
				#clock-cells = <0x00>;
				clock-div = <0x08>;
				clocks = <0x0b>;
				phandle = <0x2b>;
				clock-mult = <0x01>;
				compatible = "fixed-factor-clock";
			};

			CLK_upll_320m_div2 {
				#clock-cells = <0x00>;
				clock-div = <0x02>;
				clocks = <0x09>;
				phandle = <0x3d>;
				clock-mult = <0x01>;
				compatible = "fixed-factor-clock";
			};

			CLK_xtali_24m {
				#clock-cells = <0x00>;
				phandle = <0x05>;
				clock-frequency = <0x16e3600>;
				compatible = "fixed-clock";
			};

			CLK_xtali_12m_div16 {
				#clock-cells = <0x00>;
				clock-div = <0x10>;
				clocks = <0x0f>;
				phandle = <0x1d>;
				clock-mult = <0x01>;
				compatible = "fixed-factor-clock";
			};

			CLK_pm_fuart0 {
				#clock-cells = <0x00>;
				clocks = <0x42>;
				phandle = <0x82>;
				reg = <0x1f001d08 0x04>;
				ignore = <0x01>;
				mux-width = <0x02>;
				mux-shift = <0x0a>;
				compatible = "sstar,composite-clock";
				gate-shift = <0x08>;
			};

			CLK_otp {
				#clock-cells = <0x00>;
				clocks = <0x0f>;
				auto-enable = <0x01>;
				phandle = <0x7f>;
				reg = <0x1f207fdc 0x04>;
				mux-width = <0x02>;
				mux-shift = <0x02>;
				compatible = "sstar,composite-clock";
				gate-shift = <0x00>;
			};

			CLK_bist_mcu {
				#clock-cells = <0x00>;
				clocks = <0x1b 0x0c 0x25 0x0f>;
				auto-enable = <0x00>;
				phandle = <0x53>;
				reg = <0x1f207024 0x04>;
				mux-width = <0x02>;
				mux-shift = <0x02>;
				compatible = "sstar,composite-clock";
				gate-shift = <0x00>;
			};

			CLK_fclk2_p {
				#clock-cells = <0x00>;
				clock-div = <0x01>;
				clocks = <0x18>;
				phandle = <0x64>;
				clock-mult = <0x01>;
				compatible = "fixed-factor-clock";
			};

			CLK_upll_320m_div10 {
				#clock-cells = <0x00>;
				clock-div = <0x0a>;
				clocks = <0x09>;
				phandle = <0x39>;
				clock-mult = <0x01>;
				compatible = "fixed-factor-clock";
			};

			CLK_upll_480m_div2 {
				#clock-cells = <0x00>;
				clock-div = <0x02>;
				clocks = <0x07>;
				phandle = <0x35>;
				clock-mult = <0x01>;
				compatible = "fixed-factor-clock";
			};

			CLK_spi_synth_pll {
				#clock-cells = <0x00>;
				clocks = <0x0b>;
				phandle = <0x29>;
				compatible = "sstar,complex-clock";
			};

			CLK_pm_timer4 {
				#clock-cells = <0x00>;
				clocks = <0x1a>;
				phandle = <0xab>;
				clock-frequency = <0xb71b00>;
				compatible = "sstar,complex-clock";
			};

			CLK_sr00_mclk {
				#clock-cells = <0x00>;
				clocks = <0x2d 0x2a 0x2e 0x2b 0x2f 0x30 0x31 0x05 0x32 0x0f 0x33 0x34>;
				dfs-width = <0x05>;
				auto-enable = <0x00>;
				phandle = <0x9d>;
				reg = <0x1f207188 0x04 0x1f2071d8 0x04>;
				mux-width = <0x04>;
				mux-shift = <0x0a>;
				compatible = "sstar,composite-clock";
				dfs-shift = <0x08>;
				gate-shift = <0x08>;
			};

			CLK_ldcfeye {
				#clock-cells = <0x00>;
				clocks = <0x08 0x1b 0x24 0x0c 0x0b>;
				dfs-width = <0x05>;
				nonod-shift = <0x00>;
				auto-enable = <0x00>;
				phandle = <0x70>;
				reg = <0x1f20714c 0x04 0x1f2071e0 0x04>;
				mux-width = <0x03>;
				mux-shift = <0x02>;
				compatible = "sstar,composite-clock";
				dfs-shift = <0x00>;
				gate-shift = <0x00>;
				od-shift = <0x04>;
			};

			CLK_riu_w_clk_in {
				#clock-cells = <0x00>;
				clock-div = <0x01>;
				clocks = <0x10>;
				phandle = <0x92>;
				clock-mult = <0x01>;
				compatible = "fixed-factor-clock";
			};

			CLK_miu_rec {
				#clock-cells = <0x00>;
				clocks = <0x1c 0x1d 0x1e 0x1f>;
				auto-enable = <0x01>;
				phandle = <0x7a>;
				reg = <0x1f207060 0x04>;
				mux-width = <0x02>;
				mux-shift = <0x02>;
				compatible = "sstar,composite-clock";
				gate-shift = <0x00>;
			};

			CLK_csi0_ns_top_i {
				#clock-cells = <0x00>;
				clocks = <0x0b 0x0a 0x09 0x24>;
				dfs-width = <0x05>;
				auto-enable = <0x00>;
				phandle = <0x5a>;
				reg = <0x1f207164 0x04 0x1f2071ec 0x04>;
				mux-width = <0x02>;
				mux-shift = <0x02>;
				compatible = "sstar,composite-clock";
				dfs-shift = <0x08>;
				gate-shift = <0x00>;
			};

			CLK_ir {
				#clock-cells = <0x00>;
				clocks = <0x1a>;
				phandle = <0x6c>;
				reg = <0x1f001c84 0x04>;
				ignore = <0x01>;
				mux-width = <0x02>;
				mux-shift = <0x07>;
				compatible = "sstar,composite-clock";
				gate-shift = <0x05>;
			};

			CLK_xtali_12m_div8 {
				#clock-cells = <0x00>;
				clock-div = <0x08>;
				clocks = <0x0f>;
				phandle = <0x1c>;
				clock-mult = <0x01>;
				compatible = "fixed-factor-clock";
			};

			CLK_aesdma {
				#clock-cells = <0x00>;
				clocks = <0x14 0x1b 0x24 0x37 0x0f>;
				dfs-width = <0x05>;
				glitch-shift = <0x04>;
				auto-enable = <0x00>;
				phandle = <0x4d>;
				reg = <0x1f207184 0x04 0x1f2071e8 0x04>;
				mux-width = <0x02>;
				mux-shift = <0x02>;
				compatible = "sstar,composite-clock";
				dfs-shift = <0x00>;
				gate-shift = <0x00>;
			};

			CLK_spi_nonpm {
				#clock-cells = <0x00>;
				clocks = <0x05 0x0d 0x20 0x2b>;
				phandle = <0x3c>;
				reg = <0x1f2070c8 0x04>;
				ignore = <0x01>;
				mux-width = <0x02>;
				mux-shift = <0x02>;
				compatible = "sstar,composite-clock";
				gate-shift = <0x00>;
			};

			CLK_mpll_123m_div2 {
				#clock-cells = <0x00>;
				clock-div = <0x02>;
				clocks = <0x0c>;
				phandle = <0x2e>;
				clock-mult = <0x01>;
				compatible = "fixed-factor-clock";
			};

			CLK_mcu {
				#clock-cells = <0x00>;
				clocks = <0x1b 0x0a 0x09 0x20 0x0f>;
				glitch-shift = <0x04>;
				auto-enable = <0x01>;
				phandle = <0x10>;
				str-ignore;
				reg = <0x1f207004 0x04>;
				mux-width = <0x02>;
				mux-shift = <0x02>;
				compatible = "sstar,composite-clock";
				gate-shift = <0x00>;
			};

			CLK_pwm {
				#clock-cells = <0x00>;
				clocks = <0x0f 0x22 0x23 0x1c 0x1d 0x0d>;
				phandle = <0x8e>;
				reg = <0x1f2070e0 0x04>;
				ignore = <0x01>;
				mux-width = <0x03>;
				mux-shift = <0x0a>;
				compatible = "sstar,composite-clock";
				gate-shift = <0x08>;
			};

			CLK_fuart0_synth_out {
				#clock-cells = <0x00>;
				clocks = <0x12>;
				phandle = <0x27>;
				compatible = "sstar,complex-clock";
			};

			CLK_upll_384m_div2 {
				#clock-cells = <0x00>;
				clock-div = <0x02>;
				clocks = <0x08>;
				phandle = <0x2c>;
				clock-mult = <0x01>;
				compatible = "fixed-factor-clock";
			};

			CLK_mpll_86m {
				#clock-cells = <0x00>;
				phandle = <0x0d>;
				clock-frequency = <0x5265c00>;
				compatible = "fixed-clock";
			};

			CLK_miu_vhe_gp_p {
				#clock-cells = <0x00>;
				clock-div = <0x01>;
				clocks = <0x14>;
				phandle = <0x7c>;
				clock-mult = <0x01>;
				compatible = "fixed-factor-clock";
			};

			CLK_mspi0_p {
				#clock-cells = <0x00>;
				clock-div = <0x01>;
				clocks = <0x15>;
				phandle = <0x7d>;
				clock-mult = <0x01>;
				compatible = "fixed-factor-clock";
			};

			CLK_emac_testrx125_in_lan {
				#clock-cells = <0x00>;
				phandle = <0x3f>;
				clock-frequency = <0x7735940>;
				compatible = "fixed-clock";
			};

			CLK_upll_320m {
				#clock-cells = <0x00>;
				clocks = <0x06>;
				phandle = <0x09>;
				compatible = "sstar,complex-clock";
			};

			CLK_CLK_12M_CORE_v_live {
				#clock-cells = <0x00>;
				phandle = <0x40>;
				clock-frequency = <0xb71b00>;
				compatible = "fixed-clock";
			};

			CLK_sr03_mclk {
				#clock-cells = <0x00>;
				clocks = <0x2d 0x2a 0x2e 0x2b 0x2f 0x30 0x31 0x05 0x32 0x0f 0x33 0x34>;
				dfs-width = <0x05>;
				auto-enable = <0x00>;
				phandle = <0xa0>;
				reg = <0x1f207198 0x04 0x1f2071e4 0x04>;
				mux-width = <0x04>;
				mux-shift = <0x0a>;
				compatible = "sstar,composite-clock";
				dfs-shift = <0x08>;
				gate-shift = <0x08>;
			};

			CLK_fuart {
				#clock-cells = <0x00>;
				clocks = <0x24 0x25 0x05 0x26>;
				auto-enable = <0x00>;
				phandle = <0x65>;
				reg = <0x1f2070d0 0x04>;
				mux-width = <0x02>;
				mux-shift = <0x02>;
				compatible = "sstar,composite-clock";
				gate-shift = <0x00>;
			};

			CLK_mpll_86m_div4 {
				#clock-cells = <0x00>;
				clock-div = <0x04>;
				clocks = <0x0d>;
				phandle = <0x32>;
				clock-mult = <0x01>;
				compatible = "fixed-factor-clock";
			};

			CLK_csi0_mac_top_i {
				#clock-cells = <0x00>;
				clocks = <0x0b 0x0a 0x09 0x24>;
				dfs-width = <0x05>;
				auto-enable = <0x00>;
				phandle = <0x59>;
				reg = <0x1f207160 0x04 0x1f2071f0 0x04>;
				mux-width = <0x02>;
				mux-shift = <0x0a>;
				compatible = "sstar,composite-clock";
				dfs-shift = <0x00>;
				gate-shift = <0x08>;
			};

			CLK_miu_isp_gp_p {
				#clock-cells = <0x00>;
				clock-div = <0x01>;
				clocks = <0x14>;
				phandle = <0x79>;
				clock-mult = <0x01>;
				compatible = "fixed-factor-clock";
			};

			CLK_bist_pm {
				#clock-cells = <0x00>;
				clocks = <0x2c 0x0c 0x25 0x2b>;
				auto-enable = <0x00>;
				phandle = <0x55>;
				reg = <0x1f001d08 0x04>;
				mux-width = <0x02>;
				mux-shift = <0x02>;
				compatible = "sstar,composite-clock";
				gate-shift = <0x00>;
			};

			CLK_riu_w_clk_hemcu_gp {
				#clock-cells = <0x00>;
				clock-div = <0x01>;
				clocks = <0x10>;
				phandle = <0x91>;
				clock-mult = <0x01>;
				compatible = "fixed-factor-clock";
			};

			CLK_isp {
				#clock-cells = <0x00>;
				clocks = <0x0a 0x35 0x2c 0x09>;
				dfs-width = <0x05>;
				nonod-shift = <0x00>;
				auto-enable = <0x00>;
				phandle = <0x17>;
				reg = <0x1f207184 0x04 0x1f2071d4 0x04>;
				mux-width = <0x02>;
				mux-shift = <0x0a>;
				compatible = "sstar,composite-clock";
				dfs-shift = <0x00>;
				gate-shift = <0x08>;
				od-shift = <0x03>;
			};

			CLK_rtc {
				#clock-cells = <0x00>;
				clocks = <0x1a>;
				phandle = <0x99>;
				reg = <0x1f001c88 0x04>;
				ignore = <0x01>;
				mux-width = <0x02>;
				mux-shift = <0x02>;
				compatible = "sstar,composite-clock";
				gate-shift = <0x00>;
			};

			CLK_vif_pm {
				#clock-cells = <0x00>;
				clocks = <0x45 0x48 0x42 0x49>;
				phandle = <0xa7>;
				reg = <0x1f001d14 0x04>;
				ignore = <0x01>;
				mux-width = <0x02>;
				mux-shift = <0x02>;
				compatible = "sstar,composite-clock";
				gate-shift = <0x00>;
			};

			CLK_fuart0 {
				#clock-cells = <0x00>;
				clocks = <0x24 0x25 0x05 0x27>;
				auto-enable = <0x01>;
				phandle = <0x66>;
				reg = <0x1f2070c4 0x04>;
				mux-width = <0x02>;
				mux-shift = <0x02>;
				compatible = "sstar,composite-clock";
				gate-shift = <0x00>;
			};

			CLK_miu_sc_gp_p {
				#clock-cells = <0x00>;
				clock-div = <0x01>;
				clocks = <0x14>;
				phandle = <0x7b>;
				clock-mult = <0x01>;
				compatible = "fixed-factor-clock";
			};

			CLK_mpll_216m {
				#clock-cells = <0x00>;
				phandle = <0x1b>;
				clock-frequency = <0xcdfe600>;
				compatible = "fixed-clock";
			};

			CLK_pm_riu_w_clk_in {
				#clock-cells = <0x00>;
				phandle = <0x89>;
				clock-frequency = <0x7d00>;
				compatible = "fixed-clock";
			};

			CLK_pir_pm {
				#clock-cells = <0x00>;
				clocks = <0x42>;
				phandle = <0x81>;
				reg = <0x1f001c98 0x04>;
				ignore = <0x01>;
				mux-width = <0x02>;
				mux-shift = <0x07>;
				compatible = "sstar,composite-clock";
				gate-shift = <0x05>;
			};

			CLK_fuart1_synth_out {
				#clock-cells = <0x00>;
				clocks = <0x13>;
				phandle = <0x28>;
				compatible = "sstar,complex-clock";
			};

			CLK_ipuff {
				#clock-cells = <0x00>;
				clocks = <0x0b 0x09 0x0a 0x1b>;
				auto-enable = <0x00>;
				phandle = <0x6a>;
				reg = <0x1f207140 0x04>;
				mux-width = <0x02>;
				mux-shift = <0x0a>;
				compatible = "sstar,composite-clock";
				gate-shift = <0x08>;
			};

			CLK_ipu {
				#clock-cells = <0x00>;
				clocks = <0x0f 0x09 0x0b 0x07>;
				auto-enable = <0x00>;
				phandle = <0x69>;
				reg = <0x1f207140 0x04>;
				mux-width = <0x02>;
				mux-shift = <0x02>;
				compatible = "sstar,composite-clock";
				gate-shift = <0x00>;
			};

			CLK_real_live {
				#clock-cells = <0x00>;
				clocks = <0x40>;
				auto-enable = <0x01>;
				phandle = <0x90>;
				reg = <0x1f207028 0x04>;
				mux-width = <0x02>;
				mux-shift = <0x02>;
				compatible = "sstar,composite-clock";
				gate-shift = <0x00>;
			};

			CLK_miu_boot {
				#clock-cells = <0x00>;
				clocks = <0x0f 0x0a>;
				auto-enable = <0x00>;
				phandle = <0xb1>;
				reg = <0x1f207080 0x04>;
				mux-width = <0x01>;
				mux-shift = <0x02>;
				compatible = "sstar,composite-clock";
				gate-shift = <0x00>;
			};

			CLK_cpu_pll {
				#clock-cells = <0x00>;
				clocks = <0x0b>;
				phandle = <0x01>;
				str-ignore;
				compatible = "sstar,complex-clock";
			};

			CLK_csi1_mac_lptx_top_i {
				#clock-cells = <0x00>;
				clocks = <0x0b 0x0a 0x09 0x24>;
				dfs-width = <0x05>;
				auto-enable = <0x00>;
				phandle = <0x5b>;
				reg = <0x1f207164 0x04 0x1f2071f0 0x04>;
				mux-width = <0x02>;
				mux-shift = <0x0a>;
				compatible = "sstar,composite-clock";
				dfs-shift = <0x08>;
				gate-shift = <0x08>;
			};

			CLK_12m_mux {
				#clock-cells = <0x00>;
				phandle = <0x1a>;
				clock-frequency = <0xb71b00>;
				compatible = "fixed-clock";
			};

			CLK_sr01_mclk {
				#clock-cells = <0x00>;
				clocks = <0x2d 0x2a 0x2e 0x2b 0x2f 0x30 0x31 0x05 0x32 0x0f 0x33 0x34>;
				dfs-width = <0x05>;
				auto-enable = <0x00>;
				phandle = <0x9e>;
				reg = <0x1f207194 0x04 0x1f2071dc 0x04>;
				mux-width = <0x04>;
				mux-shift = <0x02>;
				compatible = "sstar,composite-clock";
				dfs-shift = <0x08>;
				gate-shift = <0x00>;
			};

			CLK_miic0 {
				#clock-cells = <0x00>;
				clocks = <0x2a 0x2b 0x0f>;
				auto-enable = <0x00>;
				phandle = <0x75>;
				reg = <0x1f2070dc 0x04>;
				mux-width = <0x02>;
				mux-shift = <0x02>;
				compatible = "sstar,composite-clock";
				gate-shift = <0x00>;
			};

			CLK_mpll_288m_div8 {
				#clock-cells = <0x00>;
				clock-div = <0x08>;
				clocks = <0x0a>;
				phandle = <0x31>;
				clock-mult = <0x01>;
				compatible = "fixed-factor-clock";
			};

			CLK_upll_960m {
				#clock-cells = <0x00>;
				clocks = <0x05>;
				phandle = <0x06>;
				str-ignore;
				compatible = "sstar,complex-clock";
			};

			CLK_jpe {
				#clock-cells = <0x00>;
				clocks = <0x1b 0x35 0x0a 0x2c>;
				dfs-width = <0x05>;
				auto-enable = <0x00>;
				phandle = <0x6f>;
				reg = <0x1f2071a8 0x04 0x1f2071ec 0x04>;
				mux-width = <0x02>;
				mux-shift = <0x02>;
				compatible = "sstar,composite-clock";
				dfs-shift = <0x00>;
				gate-shift = <0x00>;
			};

			CLK_sar {
				#clock-cells = <0x00>;
				clocks = <0x1a>;
				phandle = <0x9b>;
				reg = <0x1f001c88 0x04>;
				ignore = <0x01>;
				mux-width = <0x02>;
				mux-shift = <0x07>;
				compatible = "sstar,composite-clock";
				gate-shift = <0x05>;
			};

			CLK_ssi_dphy {
				#clock-cells = <0x00>;
				clocks = <0x19 0x43 0x44 0x42>;
				phandle = <0xa2>;
				reg = <0x1f001d18 0x04>;
				ignore = <0x01>;
				mux-width = <0x02>;
				mux-shift = <0x06>;
				compatible = "sstar,composite-clock";
				gate-shift = <0x04>;
			};

			CLK_sr_mclk {
				#clock-cells = <0x00>;
				phandle = <0xa1>;
				clock-frequency = <0x47868c0>;
				compatible = "fixed-clock";
			};

			CLK_upll_384m {
				#clock-cells = <0x00>;
				clocks = <0x06>;
				phandle = <0x08>;
				compatible = "sstar,complex-clock";
			};

			CLK_ven_axi {
				#clock-cells = <0x00>;
				clocks = <0x1b 0x35 0x36 0x08 0x0b 0x07 0x0a 0x2c>;
				dfs-width = <0x05>;
				nonod-shift = <0x02>;
				auto-enable = <0x00>;
				phandle = <0xa3>;
				reg = <0x1f2071a4 0x04 0x1f207ee4 0x04>;
				mux-width = <0x03>;
				mux-shift = <0x0a>;
				compatible = "sstar,composite-clock";
				dfs-shift = <0x08>;
				gate-shift = <0x08>;
				od-shift = <0x04>;
			};

			CLK_csi1_ns_top_i {
				#clock-cells = <0x00>;
				clocks = <0x0b 0x0a 0x09 0x24>;
				dfs-width = <0x05>;
				auto-enable = <0x00>;
				phandle = <0x5d>;
				reg = <0x1f207168 0x04 0x1f2071f4 0x04>;
				mux-width = <0x02>;
				mux-shift = <0x0a>;
				compatible = "sstar,composite-clock";
				dfs-shift = <0x00>;
				gate-shift = <0x08>;
			};

			CLK_disp_pixel_0 {
				#clock-cells = <0x00>;
				clocks = <0x2a 0x2b 0x0e 0x3e>;
				dfs-width = <0x05>;
				auto-enable = <0x00>;
				phandle = <0x5f>;
				reg = <0x1f207124 0x04 0x1f2071dc 0x04>;
				mux-width = <0x02>;
				mux-shift = <0x02>;
				compatible = "sstar,composite-clock";
				dfs-shift = <0x00>;
				gate-shift = <0x00>;
			};

			CLK_upll_48m {
				#clock-cells = <0x00>;
				clocks = <0x06>;
				phandle = <0xaf>;
				compatible = "sstar,complex-clock";
			};

			CLK_xtali_12m_div64 {
				#clock-cells = <0x00>;
				clock-div = <0x40>;
				clocks = <0x0f>;
				phandle = <0x1e>;
				clock-mult = <0x01>;
				compatible = "fixed-factor-clock";
			};

			CLK_live {
				#clock-cells = <0x00>;
				clocks = <0x0f>;
				auto-enable = <0x01>;
				phandle = <0x71>;
				reg = <0x1f207000 0x04>;
				mux-width = <0x02>;
				mux-shift = <0x0a>;
				compatible = "sstar,composite-clock";
				gate-shift = <0x08>;
			};

			CLK_pad_test {
				#clock-cells = <0x00>;
				clocks = <0x25 0x0c 0x2a>;
				auto-enable = <0x00>;
				phandle = <0x80>;
				reg = <0x1f207e3c 0x04>;
				mux-width = <0x02>;
				mux-shift = <0x02>;
				compatible = "sstar,composite-clock";
				gate-shift = <0x00>;
			};

			CLK_miu_p {
				#clock-cells = <0x00>;
				clock-div = <0x01>;
				clocks = <0x14>;
				phandle = <0x4a>;
				clock-mult = <0x01>;
				compatible = "fixed-factor-clock";
			};

			CLK_armpll_37p125m {
				#clock-cells = <0x00>;
				clocks = <0x01>;
				phandle = <0x34>;
				compatible = "sstar,complex-clock";
			};

			CLK_bist_isp_gp {
				#clock-cells = <0x00>;
				clocks = <0x1b 0x0c 0x25 0x0f>;
				auto-enable = <0x00>;
				phandle = <0x52>;
				reg = <0x1f207008 0x04>;
				mux-width = <0x02>;
				mux-shift = <0x06>;
				compatible = "sstar,composite-clock";
				gate-shift = <0x04>;
			};

			CLK_riubrdg {
				#clock-cells = <0x00>;
				clocks = <0x21>;
				auto-enable = <0x01>;
				phandle = <0x98>;
				reg = <0x1f207004 0x04>;
				mux-width = <0x02>;
				mux-shift = <0x0a>;
				compatible = "sstar,composite-clock";
				gate-shift = <0x08>;
			};

			CLK_hemcu {
				#clock-cells = <0x00>;
				clocks = <0x0b 0x1b>;
				auto-enable = <0x00>;
				phandle = <0x68>;
				reg = <0x1f207084 0x04>;
				mux-width = <0x02>;
				mux-shift = <0x02>;
				compatible = "sstar,composite-clock";
				gate-shift = <0x00>;
			};

			CLK_mcu_pm_p {
				#clock-cells = <0x00>;
				clock-div = <0x01>;
				clocks = <0x16>;
				phandle = <0x73>;
				clock-mult = <0x01>;
				compatible = "fixed-factor-clock";
			};

			CLK_source_mux_250m_div4 {
				#clock-cells = <0x00>;
				clock-div = <0x04>;
				clocks = <0x19>;
				phandle = <0x44>;
				clock-mult = <0x01>;
				compatible = "fixed-factor-clock";
			};

			CLK_au_sys_384 {
				#clock-cells = <0x00>;
				clocks = <0x08 0x07 0x0b>;
				auto-enable = <0x00>;
				phandle = <0x4e>;
				reg = <0x1f207fa0 0x04>;
				mux-width = <0x02>;
				mux-shift = <0x02>;
				compatible = "sstar,composite-clock";
				gate-shift = <0x00>;
			};

			CLK_rtcpll_clk {
				#clock-cells = <0x00>;
				phandle = <0x9a>;
				clock-frequency = <0xee6b280>;
				compatible = "fixed-clock";
			};

			CLK_riu_w_clk_vhe_gp {
				#clock-cells = <0x00>;
				clock-div = <0x01>;
				clocks = <0x10>;
				phandle = <0x97>;
				clock-mult = <0x01>;
				compatible = "fixed-factor-clock";
			};

			CLK_mpll_172m {
				#clock-cells = <0x00>;
				phandle = <0x24>;
				clock-frequency = <0xa408300>;
				compatible = "fixed-clock";
			};

			CLK_live_c {
				#clock-cells = <0x00>;
				clocks = <0x0f>;
				auto-enable = <0x01>;
				phandle = <0x72>;
				reg = <0x1f207000 0x04>;
				mux-width = <0x02>;
				mux-shift = <0x0a>;
				compatible = "sstar,composite-clock";
				gate-shift = <0x08>;
			};

			CLK_wdma {
				#clock-cells = <0x00>;
				clocks = <0x4a>;
				gate-enable = <0x01>;
				auto-enable = <0x00>;
				phandle = <0xb0>;
				reg = <0x1f207fec 0x04>;
				compatible = "sstar,composite-clock";
				gate-shift = <0x00>;
			};

			CLK_upll_384m_div8 {
				#clock-cells = <0x00>;
				clock-div = <0x08>;
				clocks = <0x08>;
				phandle = <0x2f>;
				clock-mult = <0x01>;
				compatible = "fixed-factor-clock";
			};

			CLK_mpll_288m {
				#clock-cells = <0x00>;
				phandle = <0x0a>;
				clock-frequency = <0x112a8800>;
				compatible = "fixed-clock";
			};

			CLK_mpll_86m_div2 {
				#clock-cells = <0x00>;
				clock-div = <0x02>;
				clocks = <0x0d>;
				phandle = <0x30>;
				clock-mult = <0x01>;
				compatible = "fixed-factor-clock";
			};

			CLK_mcu_p {
				#clock-cells = <0x00>;
				clock-div = <0x01>;
				clocks = <0x10>;
				phandle = <0x21>;
				clock-mult = <0x01>;
				compatible = "fixed-factor-clock";
			};

			CLK_mpll_345m {
				#clock-cells = <0x00>;
				phandle = <0x36>;
				clock-frequency = <0x14904840>;
				compatible = "fixed-clock";
			};

			usclk {
				clocks = <0x1a 0x49 0x47 0x42 0x40 0x4b 0x4c 0x4d 0x34 0x4e 0x4f 0x50 0x51 0x52 0x53 0x54 0x55 0x41 0x56 0x57 0x01 0x58 0x59 0x5a 0x5b 0x5c 0x5d 0x5e 0x5f 0x0e 0x3e 0x60 0x61 0x62 0x3f 0x18 0x63 0x64 0x65 0x66 0x12 0x27 0x67 0x13 0x28 0x11 0x26 0x68 0x69 0x6a 0x6b 0x6c 0x17 0x6d 0x6e 0x6f 0x70 0x71 0x72 0x10 0x21 0x16 0x73 0x74 0x75 0x76 0x77 0x78 0x79 0x4a 0x7a 0x7b 0x7c 0x14 0x0c 0x2e 0x24 0x1b 0x0a 0x25 0x2a 0x31 0x36 0x0b 0x2d 0x20 0x2b 0x0d 0x33 0x30 0x32 0x15 0x7d 0x7e 0x7f 0x37 0x80 0x81 0x82 0x83 0x84 0x85 0x86 0x87 0x88 0x89 0x8a 0x8b 0x8c 0x8d 0x8e 0x8f 0x90 0x91 0x92 0x93 0x94 0x95 0x96 0x97 0x98 0x99 0x9a 0x9b 0x9c 0x19 0x43 0x44 0x45 0x46 0x48 0x3c 0x29 0x9d 0x9e 0x9f 0xa0 0xa1 0xa2 0x09 0x39 0x3a 0x3d 0x38 0x08 0x2c 0x2f 0x07 0x35 0xa3 0xa4 0xa5 0xa6 0xa7 0xa8 0xa9 0x0f 0x1f 0x1d 0x22 0x23 0x3b 0x1e 0x1c 0x05 0xaa 0xab 0xac 0xad 0xae 0xaf 0xb0 0xb1>;
				phandle = <0xbe>;
				clock-count = <0xab>;
				compatible = "usclk";
			};

			CLK_mfe {
				#clock-cells = <0x00>;
				clocks = <0x0a 0x09 0x0b 0x07 0x1b 0x08 0x36 0x25>;
				dfs-width = <0x05>;
				nonod-shift = <0x02>;
				auto-enable = <0x00>;
				phandle = <0x74>;
				reg = <0x1f2071a4 0x04 0x1f207ee8 0x04>;
				mux-width = <0x03>;
				mux-shift = <0x02>;
				compatible = "sstar,composite-clock";
				dfs-shift = <0x00>;
				gate-shift = <0x00>;
				od-shift = <0x03>;
			};

			CLK_vhe {
				#clock-cells = <0x00>;
				clocks = <0x1b 0x35 0x36 0x08 0x0b 0x07 0x0a 0x2c>;
				dfs-width = <0x05>;
				nonod-shift = <0x02>;
				auto-enable = <0x01>;
				phandle = <0xa6>;
				reg = <0x1f2071a0 0x04 0x1f207ee4 0x04>;
				mux-width = <0x03>;
				mux-shift = <0x02>;
				compatible = "sstar,composite-clock";
				dfs-shift = <0x00>;
				gate-shift = <0x07>;
				od-shift = <0x04>;
			};

			CLK_odclk {
				#clock-cells = <0x00>;
				clocks = <0x0d 0x30 0x32>;
				auto-enable = <0x00>;
				phandle = <0x7e>;
				reg = <0x1f207198 0x04>;
				mux-width = <0x02>;
				mux-shift = <0x02>;
				compatible = "sstar,composite-clock";
				gate-shift = <0x00>;
			};

			CLK_xtali_12m_div4 {
				#clock-cells = <0x00>;
				clock-div = <0x04>;
				clocks = <0x0f>;
				phandle = <0x23>;
				clock-mult = <0x01>;
				compatible = "fixed-factor-clock";
			};

			CLK_12m_mux_div2 {
				#clock-cells = <0x00>;
				clock-div = <0x02>;
				clocks = <0x1a>;
				phandle = <0x49>;
				clock-mult = <0x01>;
				compatible = "fixed-factor-clock";
			};

			CLK_mpll_432m_div4 {
				#clock-cells = <0x00>;
				clock-div = <0x04>;
				clocks = <0x0b>;
				phandle = <0x20>;
				clock-mult = <0x01>;
				compatible = "fixed-factor-clock";
			};

			CLK_dsc_enc1 {
				#clock-cells = <0x00>;
				clocks = <0x2c 0x3d 0x25 0x1b>;
				dfs-width = <0x05>;
				nonod-shift = <0x00>;
				auto-enable = <0x00>;
				phandle = <0x61>;
				reg = <0x1f207118 0x04 0x1f207fd4 0x04>;
				mux-width = <0x02>;
				mux-shift = <0x0a>;
				compatible = "sstar,composite-clock";
				dfs-shift = <0x08>;
				gate-shift = <0x08>;
				od-shift = <0x03>;
			};

			CLK_24m_mux {
				#clock-cells = <0x00>;
				phandle = <0x42>;
				clock-frequency = <0x16e3600>;
				compatible = "fixed-clock";
			};

			CLK_xtali_12m {
				#clock-cells = <0x00>;
				phandle = <0x0f>;
				clock-frequency = <0xb71b00>;
				compatible = "fixed-clock";
			};

			CLK_pwr_ctl {
				#clock-cells = <0x00>;
				clocks = <0x1d 0x1c 0x0f>;
				auto-enable = <0x01>;
				phandle = <0x8f>;
				reg = <0x1f207010 0x04>;
				mux-width = <0x02>;
				mux-shift = <0x02>;
				compatible = "sstar,composite-clock";
				gate-shift = <0x00>;
			};

			CLK_xtali_12m_div2 {
				#clock-cells = <0x00>;
				clock-div = <0x02>;
				clocks = <0x0f>;
				phandle = <0x22>;
				clock-mult = <0x01>;
				compatible = "fixed-factor-clock";
			};

			CLK_fuart1 {
				#clock-cells = <0x00>;
				clocks = <0x24 0x25 0x05 0x28>;
				auto-enable = <0x00>;
				phandle = <0x67>;
				reg = <0x1f2070c4 0x04>;
				mux-width = <0x02>;
				mux-shift = <0x06>;
				compatible = "sstar,composite-clock";
				gate-shift = <0x04>;
			};

			CLK_dsc_dec1 {
				#clock-cells = <0x00>;
				clocks = <0x2c 0x3d 0x25 0x1b>;
				dfs-width = <0x05>;
				nonod-shift = <0x00>;
				auto-enable = <0x00>;
				phandle = <0x60>;
				reg = <0x1f207130 0x04 0x1f207fd8 0x04>;
				mux-width = <0x02>;
				mux-shift = <0x0a>;
				compatible = "sstar,composite-clock";
				dfs-shift = <0x08>;
				gate-shift = <0x08>;
				od-shift = <0x03>;
			};

			CLK_miu2x_p {
				#clock-cells = <0x00>;
				clock-div = <0x01>;
				clocks = <0x14>;
				phandle = <0x78>;
				clock-mult = <0x01>;
				compatible = "fixed-factor-clock";
			};

			CLK_fuart0_synth_in {
				#clock-cells = <0x00>;
				clocks = <0x0b 0x1b>;
				auto-enable = <0x00>;
				phandle = <0x12>;
				reg = <0x1f2070b4 0x04>;
				mux-width = <0x02>;
				mux-shift = <0x06>;
				compatible = "sstar,composite-clock";
				gate-shift = <0x04>;
			};

			CLK_source_mux_250m_div6 {
				#clock-cells = <0x00>;
				clock-div = <0x06>;
				clocks = <0x19>;
				phandle = <0x46>;
				clock-mult = <0x01>;
				compatible = "fixed-factor-clock";
			};

			CLK_pm_pwr_ctl {
				#clock-cells = <0x00>;
				clocks = <0x42>;
				phandle = <0x88>;
				reg = <0x1f001d0c 0x04>;
				ignore = <0x01>;
				mux-width = <0x02>;
				mux-shift = <0x02>;
				compatible = "sstar,composite-clock";
				gate-shift = <0x00>;
			};

			CLK_miic1 {
				#clock-cells = <0x00>;
				clocks = <0x2a 0x2b 0x0f>;
				auto-enable = <0x00>;
				phandle = <0x76>;
				reg = <0x1f2070dc 0x04>;
				mux-width = <0x02>;
				mux-shift = <0x0a>;
				compatible = "sstar,composite-clock";
				gate-shift = <0x08>;
			};

			CLK_miupll_clk {
				#clock-cells = <0x00>;
				clocks = <0x05>;
				phandle = <0x14>;
				compatible = "sstar,complex-clock";
			};

			CLK_otp_p {
				#clock-cells = <0x00>;
				phandle = <0x37>;
				clock-frequency = <0xb71b00>;
				compatible = "fixed-clock";
			};
		};

		sstar_sdmmc0 {
			en-eight-phase = [00];
			pwr-on-delay = <0x01>;
			max-frequency = <0x2faf080>;
			clocks = <0x9c 0x8a 0x16>;
			pwr-save-reg = <0x1f008800 0x200>;
			rx-clk-phase = <0x00>;
			cifd-mcg-off = [00];
			support-cmd23 = [01];
			rx-eight-phase = [00];
			bus-width = <0x04>;
			tx-clk-phase = <0x00>;
			status = "ok";
			interrupts = <0x00 0x32 0x04 0x00 0x23 0x04>;
			phandle = <0xc4>;
			interrupt-names = "mie0_irq\0mie1_irq";
			non-removable;
			reg = <0x1f008400 0x200>;
			en-clk-phase = [00];
			clk-driving = <0x01>;
			pwr-off-delay = <0x1e>;
			ip-order = [01];
			tx-eight-phase = [00];
			cifd-reg = <0x1f008600 0x200>;
			pll-reg = <0x1f283200 0x200>;
			clock-names = "clk_sdmmc0\0clk_sdmmc1\0pm_mcu_sdmmc1";
			rev-cdz = [00];
			trans-mode = [01];
			data-driving = <0x01>;
			pad-order = [00];
			no-sdio;
			compatible = "sstar,sdmmc";
			cmd-driving = <0x01>;
			no-sd;
			fake-cdz = [00];
			cap-mmc-highspeed;
		};

		aesdma {
			clocks = <0x4d>;
			status = "ok";
			interrupts = <0x00 0x37 0x04>;
			compatible = "sstar,aesdma";
		};

		timer2@0x1F0060C0 {
			clocks = <0x73>;
			status = "ok";
			interrupts = <0x00 0xa0 0x04>;
			phandle = <0xc8>;
			reg = <0x1f0060c0 0x40>;
			compatible = "sstar,timer";
		};

		timer11@0x1F2CDF00 {
			clocks = <0x10>;
			status = "ok";
			interrupts = <0x00 0xbe 0x01>;
			phandle = <0xd1>;
			reg = <0x1f2cdf00 0x40>;
			compatible = "sstar,timer";
		};

		bdma0 {
			clocks = <0xb2>;
			status = "ok";
			interrupts = <0x00 0x48 0x04>;
			reg = <0x1f200400 0x80>;
			compatible = "sstar,bdma0";
		};

		miu {
			status = "ok";
			interrupts = <0x00 0x24 0x04>;
			compatible = "sstar,miu";
		};

		cmdq0 {
			clocks = <0x10>;
			status = "ok";
			interrupts = <0x00 0x31 0x04>;
			compatible = "sstar,cmdq0";
		};

		timer6@0x1F0061C0 {
			clocks = <0xad>;
			status = "ok";
			interrupts = <0x00 0xa0 0x04>;
			phandle = <0xcc>;
			reg = <0x1f0061c0 0x40>;
			compatible = "sstar,timer";
			clock-on-demand;
		};

		vpe {
			clocks = <0x18 0xa4>;
			status = "ok";
			interrupts = <0x00 0x34 0x04 0x00 0x5a 0x04 0x00 0x5d 0x04>;
			phandle = <0xec>;
			compatible = "sigmastar,vpe";
		};

		disp {
			clocks = <0x18 0x5f 0x0e>;
			status = "ok";
			interrupts = <0x00 0x20 0x04>;
			phandle = <0xdb>;
			compatible = "sstar,disp";
		};

		sstar_pm_main_intc {
			interrupt-parent = <0x03>;
			status = "ok";
			interrupts = <0x00 0x30 0x04 0x00 0x30 0x04>;
			phandle = <0xbb>;
			#interrupt-cells = <0x01>;
			interrupt-controller;
			compatible = "sstar,pm-main-intc";
		};

		bdma7 {
			clocks = <0xb2>;
			status = "ok";
			interrupts = <0x00 0x49 0x04>;
			reg = <0x1f201780 0x80>;
			compatible = "sstar,bdma7";
		};

		sstar_pm_gpi_intc {
			interrupt-parent = <0x03>;
			interrupts = <0x00 0x22 0x04>;
			phandle = <0xb5>;
			#interrupt-cells = <0x01>;
			interrupt-controller;
			compatible = "sstar,pm-gpi-intc";
		};

		isp {
			clocks = <0x17 0x18 0x61 0x60>;
			status = "ok";
			interrupts = <0x00 0x39 0x04>;
			phandle = <0xd7>;
			clock-frequency-index = <0x00>;
			banks = <0x1302>;
			io_phy_addr = <0x1f000000>;
			compatible = "isp";
		};

		pmu {
			interrupt-parent = <0x04>;
			interrupts = <0x00 0x0a 0x04 0x00 0x10 0x04 0x00 0x16 0x04 0x00 0x1c 0x04>;
			compatible = "arm,cortex-a53-pmu";
		};

		cmdq2 {
			clocks = <0x10>;
			status = "ok";
			interrupts = <0x00 0x31 0x04>;
			compatible = "sstar,cmdq2";
		};

		timer7@0x1F006440 {
			clocks = <0xae>;
			status = "ok";
			interrupts = <0x00 0xa0 0x04>;
			phandle = <0xcd>;
			reg = <0x1f006440 0x40>;
			compatible = "sstar,timer";
			clock-on-demand;
		};

		pwm@0x1F203440 {
			clocks = <0x8e>;
			channel = <0x05>;
			status = "ok";
			interrupts = <0x00 0x5b 0x04>;
			phandle = <0xe5>;
			reg = <0x1f203440 0x37>;
			group = <0x01>;
			#pwm-cells = <0x03>;
			clk-select = <0x00>;
			compatible = "sstar,pwm";
		};

		cpu_power {
			init_voltage = <0x384>;
			status = "ok";
			vid_gpio = <0x3d>;
			base_voltage = <0x384>;
			compatible = "sstar,voltage-idac-ctrl";
		};

		i2c@1f222a00 {
			t-hd-sto = <0x00>;
			t-hd-sta = <0x00>;
			output-mode = <0x02>;
			clocks = <0x76>;
			status = "ok";
			interrupts = <0x00 0x44 0x04>;
			phandle = <0xef>;
			t-su-sta = <0x00>;
			reg = <0x1f222a00 0x200>;
			t-su-sto = <0x00>;
			#address-cells = <0x01>;
			#size-cells = <0x00>;
			group = <0x01>;
			speed = <0x30d40>;
			compatible = "sstar,i2c";
			dma-enable;
		};

		pwm@0x1F0034C0 {
			clocks = <0x87>;
			channel = <0x0b>;
			status = "ok";
			phandle = <0xeb>;
			reg = <0x1f0034c0 0x37>;
			#pwm-cells = <0x03>;
			clk-select = <0x00>;
			compatible = "sstar,pwm";
		};

		light_misc_control {
			status = "ok";
			lightsensor-i2c = <0x00>;
			ircut-pad = <0x35 0x34>;
			compatible = "sstar,light_misc_control";
			ir-pad = <0x2f>;
		};

		uart1@1F221200 {
			clocks = <0x67>;
			status = "ok";
			interrupts = <0x00 0x45 0x04 0x00 0x5c 0x04 0x00 0x5c 0x04>;
			phandle = <0xc0>;
			reg = <0x1f221200 0x100 0x1f221c00 0x100>;
			tx_fifo_level = <0x00>;
			digmux = <0x03>;
			compatible = "sstar,uart";
			dma-enable;
			rx_fifo_level = <0x00>;
		};

		nandflash0 {
			status = "ok";
			engine = <0x00>;
			compatible = "sstar-nandflash";
			cs-select = <0x00>;
			fcie-interface = <0x00>;
		};

		sstar_sdmmc1 {
			pwr-pad = <0x2c>;
			no-mmc;
			en-eight-phase = [00];
			pwr-on-delay = <0x01>;
			max-frequency = <0x2dc6c00>;
			clocks = <0x9c 0x8a 0x16>;
			cap-sd-highspeed;
			pwr-save-reg = <0x1f282a00 0x200>;
			rx-clk-phase = <0x00>;
			cdz-pad = <0x14>;
			cifd-mcg-off = [00];
			support-cmd23 = [01];
			rx-eight-phase = [00];
			bus-width = <0x04>;
			tx-clk-phase = <0x00>;
			status = "ok";
			interrupts = <0x00 0x32 0x04 0x00 0xb7 0x04>;
			cap-sdio-irq;
			phandle = <0xc5>;
			interrupt-names = "mie0_irq\0cdz_slot0_irq";
			reg = <0x1f282600 0x200>;
			en-clk-phase = [00];
			clk-driving = <0x01>;
			pwr-off-delay = <0x1e>;
			ip-order = [00];
			tx-eight-phase = [00];
			cifd-reg = <0x1f282800 0x200>;
			sdio-use-1bit = [00];
			pll-reg = <0x1f283400 0x200>;
			clock-names = "clk_sdmmc0\0clk_sdmmc1\0pm_mcu_sdmmc1";
			rev-cdz = [00];
			trans-mode = [01];
			data-driving = <0x01>;
			pad-order = [00];
			compatible = "sstar,sdmmc";
			cmd-driving = <0x01>;
			fake-cdz = <0x00>;
			cap-mmc-highspeed;
			support-runtime-pm = [00];
		};

		cmdq5 {
			clocks = <0x10>;
			status = "ok";
			interrupts = <0x00 0x4d 0x04>;
			compatible = "sstar,cmdq5";
		};

		sstar_gpi_intc {
			interrupt-parent = <0x03>;
			interrupts = <0x00 0x58 0x04>;
			phandle = <0xbc>;
			#interrupt-cells = <0x01>;
			interrupt-controller;
			compatible = "sstar,gpi-intc";
		};

		msb250x-udc-p0 {
			ep_name = "ep0\0ep1\0ep2\0ep3\0ep4\0ep5\0ep6";
			ep_maxpkt_limit = <0x40 0x400 0x400 0x40 0x200 0x200 0x40>;
			clocks = <0x06>;
			status = "okay";
			interrupts = <0x00 0x40 0x04>;
			ep_fifo_size = <0x40 0x2000 0x400 0x40 0x200 0x200 0x40>;
			interrupt-names = "msb250x_udc_p0";
			reg = <0x1f284200 0x200 0x1f284600 0x200 0x1f284a00 0x400 0x1f203c00 0x200>;
			dma_channel_num = <0x07>;
			reg-names = "utmi\0usb0\0otg\0chiptop";
			compatible = "sstar,msb250x-udc";
			maximum-speed = "high-speed";
		};

		scl {
			status = "ok";
			phandle = <0xe2>;
			compatible = "sstar,scl";
		};

		pwm@0x1F003440 {
			clocks = <0x87>;
			channel = <0x09>;
			status = "ok";
			phandle = <0xe9>;
			reg = <0x1f003440 0x37>;
			#pwm-cells = <0x03>;
			clk-select = <0x00>;
			compatible = "sstar,pwm";
		};

		mmu {
			status = "ok";
			interrupts = <0x00 0x2e 0x04>;
			compatible = "sstar,mmu";
		};

		bdma8 {
			clocks = <0xb2>;
			status = "ok";
			interrupts = <0x00 0x4b 0x04>;
			reg = <0x1f008a00 0x80>;
			compatible = "sstar,bdma8";
		};

		cmdq6 {
			clocks = <0x10>;
			status = "ok";
			interrupts = <0x00 0x4d 0x04>;
			compatible = "sstar,cmdq6";
		};

		cmdq4 {
			clocks = <0x10>;
			status = "ok";
			interrupts = <0x00 0x4d 0x04>;
			compatible = "sstar,cmdq4";
		};

		bc@0x1f284400 {
			reg-io-width = <0x02>;
			phandle = <0xb9>;
			reg = <0x1f284400 0x200>;
			compatible = "syscon";
		};

		ispalgo {
			status = "ok";
			phandle = <0xd8>;
			compatible = "sstar,ispalgo";
		};

		padmux {
			schematic = <0x03 0x0e 0x50101 0x00 0x0e 0x50102 0x47 0x00 0xe0001 0x15 0x2c 0x20006 0x16 0x2c 0x20005 0x17 0x2c 0x20003 0x18 0x2c 0x20004 0x19 0x2c 0x20008 0x1a 0x2c 0x20007 0x2c 0x00 0x20001 0x14 0x2e 0x20002 0x71 0xffff 0x00>;
			status = "ok";
			compatible = "sstar,padmux";
		};

		pwm@0x1F203200 {
			clocks = <0x8e>;
			channel = <0x00>;
			status = "ok";
			interrupts = <0x00 0x5b 0x04>;
			phandle = <0xd4>;
			reg = <0x1f203200 0x37>;
			group = <0x00>;
			#pwm-cells = <0x03>;
			clk-select = <0x00>;
			compatible = "sstar,pwm";
		};

		rtcpwc {
			status = "ok";
			interrupts = <0x00 0x28 0x04>;
			phandle = <0xd3>;
			io4-enable = <0x03>;
			io5-enable = <0x07>;
			reg = <0x1f006800 0x200>;
			compatible = "sstar,rtcpwc";

			io1 {
				interrupt-parent = <0xb5>;
				interrupts = <0x3b>;
				num = <0x01>;
				keycode = <0x8f>;
			};
		};

		gpio {
			status = "ok";
			phandle = <0xd2>;
			compatible = "sstar,gpio";
		};

		u2phy1 {
			#phy-cells = <0x00>;
			status = "okay";
			phandle = <0xba>;
			syscon-utmi = <0xb6>;
			syscon-usbc = <0xb8>;
			syscon-bc = <0xb9>;
			syscon-uhc = <0xb7>;
			compatible = "sstar, u2phy1";
		};

		pwm@0x1F203300 {
			clocks = <0x8e>;
			channel = <0x02>;
			status = "ok";
			interrupts = <0x00 0x5b 0x04>;
			phandle = <0xd6>;
			reg = <0x1f203300 0x37>;
			group = <0x00>;
			#pwm-cells = <0x03>;
			clk-select = <0x00>;
			compatible = "sstar,pwm";
		};

		cmdq1 {
			clocks = <0x10>;
			status = "ok";
			interrupts = <0x00 0x31 0x04>;
			compatible = "sstar,cmdq1";
		};

		jpe@0x1F246400 {
			clocks = <0x6f>;
			status = "ok";
			interrupts = <0x00 0x3d 0x04>;
			phandle = <0xe0>;
			interrupt-names = "jpe-irq0";
			reg = <0x1f246400 0x100 0x1f246600 0x100>;
			clock-names = "CKG_jpe";
			clk-select = <0x00>;
			compatible = "sstar,cedric-jpe";
		};

		norflash0 {
			status = "ok";
			engine = <0x00>;
			compatible = "sstar-norflash";
			cs-select = <0x00>;
		};

		uart0@1F221000 {
			clocks = <0x66>;
			status = "ok";
			interrupts = <0x00 0x42 0x04 0x00 0x43 0x04 0x00 0x43 0x04>;
			phandle = <0xbf>;
			reg = <0x1f221000 0x100 0x1f220e00 0x100>;
			tx_fifo_level = <0x00>;
			digmux = <0x00>;
			compatible = "sstar,uart";
			dma-enable;
			rx_fifo_level = <0x00>;
		};

		core_power {
			init_voltage = <0x384>;
			status = "ok";
			vid_gpio = <0x3e>;
			base_voltage = <0x384>;
			compatible = "sstar,voltage-idac-ctrl";
		};

		pnl {
			status = "ok";
			phandle = <0xda>;
			compatible = "sstar,pnl";
		};

		hst0to1 {
			status = "ok";
			interrupts = <0x00 0xa3 0x04>;
			compatible = "sstar,hst0to1";
		};

		ldc0 {
			clocks = <0x70>;
			status = "ok";
			interrupts = <0x00 0x5e 0x04>;
			phandle = <0xe1>;
			reg = <0x1f365000 0x100 0x1f365200 0x100>;
			compatible = "sstar,ldc";
		};

		vif {
			clocks = <0x17>;
			status = "ok";
			interrupts = <0x00 0x59 0x04 0x00 0x38 0x04>;
			phandle = <0xde>;
			reg = <0x1f261000 0x600 0x1f260400 0x200 0x1f260600 0x200 0x1f207c00 0x200 0x1f207800 0x200 0x1f227400 0x200 0x1f207000 0x200 0x1f207e00 0x200 0x1f000000 0x400000 0x1f203c00 0x200>;
			compatible = "sstar,vif";
		};

		usbc@0x1f284600 {
			reg-io-width = <0x02>;
			phandle = <0xb8>;
			reg = <0x1f284600 0x200>;
			compatible = "syscon";
		};

		bdma10 {
			clocks = <0xb2>;
			status = "ok";
			interrupts = <0x00 0x4b 0x04>;
			reg = <0x1f008b00 0x80>;
			compatible = "sstar,bdma10";
		};

		bdma9 {
			clocks = <0xb2>;
			status = "ok";
			interrupts = <0x00 0x4b 0x04>;
			reg = <0x1f008a80 0x80>;
			compatible = "sstar,bdma9";
		};

		sound {
			i2s-trx-shared-padmux = <0x00>;
			i2s-pcm = <0x00>;
			hpf-dmic-level = <0x01 0x03>;
			i2s-tx0-tdm-ws-inv = <0x00>;
			i2s-rx0-tdm-ws-pgm = <0x00>;
			clocks = <0xaf 0x4e 0x4f>;
			digmic-padmux = <0x05>;
			keep-i2s-clk = <0x00>;
			i2s-mck-padmux = <0x07>;
			keep_adc_power_on = <0x00>;
			i2s-tx-short-ff-mode = <0x00>;
			i2s-rx0-tdm-ch-swap = <0x00 0x00 0x00 0x00>;
			status = "ok";
			i2s-rx-padmux = <0x07>;
			interrupts = <0x00 0x4a 0x04>;
			i2s-tx-padmux = <0x06>;
			adc-out-sel = <0x00 0x01>;
			i2s-rx-short-ff-mode = <0x00>;
			i2s-tx0-tdm-ws-pgm = <0x00>;
			i2s-rx0-tdm-ws-inv = <0x00>;
			hpf-adc1-level = <0x01 0x03>;
			i2s-tx0-tdm-active-slot = <0xffff>;
			i2s-rx0-tdm-ws-width = <0x00>;
			dmic-bck-ext-mode = <0x00>;
			adc-ch-inmux = <0x00>;
			i2s-tx0-tdm-bck-inv = <0x00>;
			i2s-tx0-tdm-ws-width = <0x00>;
			i2s-rx0-tdm-bck-inv = <0x00>;
			i2s-rx-mode = <0x00>;
			compatible = "sstar,audio";
			amp-pad = <0x0a 0x01 0x0a 0x01>;
			i2s-tx0-tdm-ch-swap = <0x00 0x00 0x00 0x00>;
			keep_dac_power_on = <0x00>;
			dmic-bck-mode = <0x03 0x06 0x09 0x0b>;
		};

		sstar-ehci-1 {
			phys = <0xba>;
			clocks = <0x06>;
			support_high_2g_access_patch;
			status = "ok";
			interrupts = <0x00 0x3f 0x04>;
			syscon-utmi = <0xb6>;
			syscon-usbc = <0xb8>;
			reg = <0x1f284800 0x200>;
			phy-names = "usb";
			syscon-bc = <0xb9>;
			reg-names = "ehc_base";
			compatible = "sstar-ehci-1";
		};

		pwm@0x1F203480 {
			clocks = <0x8e>;
			channel = <0x06>;
			status = "ok";
			interrupts = <0x00 0x5b 0x04>;
			phandle = <0xe6>;
			reg = <0x1f203480 0x37>;
			group = <0x01>;
			#pwm-cells = <0x03>;
			clk-select = <0x00>;
			compatible = "sstar,pwm";
		};

		bdma4 {
			clocks = <0xb2>;
			status = "ok";
			interrupts = <0x00 0x49 0x04>;
			reg = <0x1f201600 0x80>;
			compatible = "sstar,bdma4";
		};

		timer0@0x1F006040 {
			clocks = <0x73>;
			status = "ok";
			interrupts = <0x00 0xa0 0x04>;
			phandle = <0xc6>;
			reg = <0x1f006040 0x40>;
			compatible = "sstar,timer";
		};

		bdma3 {
			clocks = <0xb2>;
			status = "ok";
			interrupts = <0x00 0x48 0x04>;
			reg = <0x1f200580 0x80>;
			compatible = "sstar,bdma3";
		};

		csi {
			clocks = <0x58 0x59 0x5a 0x5b 0x5c 0x5d>;
			csi_sr0_lane_num = <0x04>;
			clkgen_banks = <0x1038>;
			status = "ok";
			interrupts = <0x00 0x41 0x04>;
			csi_sr2_lane_select = <0x02 0x01 0x00>;
			phandle = <0xdd>;
			csi_sr2_lane_num = <0x02>;
			banks = <0x153c 0x153d 0x153e 0x1538 0x153a 0x153b>;
			csi_sr2_lane_pn_swap = <0x00 0x00 0x00>;
			csi_sr0_lane_select = <0x02 0x01 0x03 0x00 0x04>;
			csi_sr0_lane_pn_swap = <0x00 0x00 0x00 0x00 0x00>;
			io_phy_addr = <0x1f000000>;
			compatible = "sstar,csi";
			atop_banks = <0x153f>;
		};

		venc {
			interrupt-parent = <0x03>;
			clocks = <0xa6 0x74 0xa3 0xa5 0xa4>;
			status = "ok";
			interrupts = <0x00 0x3a 0x04>;
			interrupt-names = "mhe-irq";
			reg = <0x1f34d000 0x800 0x1f2c5400 0x100 0x1f203c00 0x100 0x1f207800 0x100 0x1f2c5400 0x100>;
			clock-names = "CKG_venc";
			reg-names = "vpu-bit\0venc-brige\0hw-uart0\0hw-uart1\0venc-gp";
			compatible = "sstar,venc";
		};

		i2c@1f222800 {
			t-hd-sto = <0x00>;
			t-hd-sta = <0x00>;
			output-mode = <0x02>;
			clocks = <0x75>;
			status = "ok";
			interrupts = <0x00 0x44 0x04>;
			phandle = <0xc2>;
			t-su-sta = <0x00>;
			reg = <0x1f222800 0x200>;
			t-su-sto = <0x00>;
			#address-cells = <0x01>;
			#size-cells = <0x00>;
			group = <0x00>;
			speed = <0x30d40>;
			compatible = "sstar,i2c";
			dma-enable;
		};

		pwm@0x1F003400 {
			clocks = <0x87>;
			channel = <0x08>;
			status = "ok";
			phandle = <0xe8>;
			reg = <0x1f003400 0x37>;
			#pwm-cells = <0x03>;
			clk-select = <0x00>;
			compatible = "sstar,pwm";
		};

		sensorif {
			vif_sr2_mclk_37p125 = <0x01>;
			snr2_mipi_i2c = <0x01>;
			snr_sr0_mipi_mclk_mode = <0x01>;
			clocks = <0x9d 0x9e>;
			snr_sr0_mipi_mode = <0x01>;
			snr_sr0_mipi_rst_mode = <0x01>;
			phandle = <0xdf>;
			snr_sr2_mipi_rst_mode = <0x01>;
			snr_sr0_mipi_pdn_mode = <0x00>;
			snr_sr2_mipi_mclk_mode = <0x01>;
			snr_sr2_mipi_mode = <0x03>;
			vif_sr0_mclk_37p125 = <0x01>;
			snr0_mipi_i2c = <0x01>;
			compatible = "sstar,sensorif";
			snr_sr2_mipi_pdn_mode = <0x00>;
		};

		cpufreq {
			clocks = <0x9b>;
			status = "ok";
			compatible = "sstar,infinity-cpufreq";
		};

		sstar_main_intc {
			interrupt-parent = <0x04>;
			phandle = <0x03>;
			#interrupt-cells = <0x03>;
			interrupt-controller;
			#address-cells = <0x01>;
			#size-cells = <0x01>;
			compatible = "sstar,main-intc";
		};

		i2c@1f222c00 {
			t-hd-sto = <0x00>;
			t-hd-sta = <0x00>;
			output-mode = <0x02>;
			clocks = <0x77>;
			status = "ok";
			interrupts = <0x00 0x3c 0x04>;
			phandle = <0xf0>;
			t-su-sta = <0x00>;
			reg = <0x1f222c00 0x200>;
			t-su-sto = <0x00>;
			#address-cells = <0x01>;
			#size-cells = <0x00>;
			group = <0x02>;
			speed = <0x30d40>;
			compatible = "sstar,i2c";
			dma-enable;
		};

		timer5@0x1F006180 {
			clocks = <0xac>;
			status = "ok";
			interrupts = <0x00 0xa0 0x04>;
			phandle = <0xcb>;
			reg = <0x1f006180 0x40>;
			compatible = "sstar,timer";
			clock-on-demand;
		};

		pwm@0x1F203280 {
			clocks = <0x8e>;
			channel = <0x01>;
			status = "ok";
			interrupts = <0x00 0x5b 0x04>;
			phandle = <0xd5>;
			reg = <0x1f203280 0x37>;
			group = <0x00>;
			#pwm-cells = <0x03>;
			clk-select = <0x00>;
			compatible = "sstar,pwm";
		};

		fuart@1F220400 {
			clocks = <0x65>;
			status = "ok";
			interrupts = <0x00 0x4f 0x04 0x00 0x50 0x04 0x00 0x50 0x04>;
			phandle = <0xc1>;
			reg = <0x1f220400 0x100 0x1f220600 0x100>;
			tx_fifo_level = <0x00>;
			digmux = <0x01>;
			compatible = "sstar,uart";
			dma-enable;
			rx_fifo_level = <0x00>;
			sctp_enable = <0x00>;
		};

		utmi@0x1f284200 {
			reg-io-width = <0x02>;
			phandle = <0xb6>;
			reg = <0x1f284200 0x200>;
			compatible = "syscon";
		};

		bdma2 {
			clocks = <0xb2>;
			status = "ok";
			interrupts = <0x00 0x48 0x04>;
			reg = <0x1f200500 0x80>;
			compatible = "sstar,bdma2";
		};

		pwm@0x1F003480 {
			clocks = <0x87>;
			channel = <0x0a>;
			status = "ok";
			phandle = <0xea>;
			reg = <0x1f003480 0x37>;
			#pwm-cells = <0x03>;
			clk-select = <0x00>;
			compatible = "sstar,pwm";
		};

		cmdq7 {
			clocks = <0x10>;
			status = "ok";
			interrupts = <0x00 0x4d 0x04>;
			compatible = "sstar,cmdq7";
		};

		dla {
			clocks = <0x6b 0x69 0x6a>;
			status = "ok";
			interrupts = <0x00 0x55 0x04>;
			compatible = "sstar,dla";
		};

		rng {
			clocks = <0xb1>;
			status = "ok";
			compatible = "sstar,rng";
		};

		ispmid {
			status = "ok";
			phandle = <0xd9>;
			compatible = "sstar,ispmid";
		};

		uhc@0x1f284800 {
			reg-io-width = <0x02>;
			phandle = <0xb7>;
			reg = <0x1f284800 0x200>;
			compatible = "syscon";
		};

		timer4@0x1F006140 {
			clocks = <0xab>;
			status = "ok";
			interrupts = <0x00 0xa0 0x04>;
			phandle = <0xca>;
			reg = <0x1f006140 0x40>;
			compatible = "sstar,timer";
			clock-on-demand;
		};

		bdma6 {
			clocks = <0xb2>;
			status = "ok";
			interrupts = <0x00 0x49 0x04>;
			reg = <0x1f201700 0x80>;
			compatible = "sstar,bdma6";
		};

		timer9@0x1F2CDE80 {
			clocks = <0x10>;
			status = "ok";
			interrupts = <0x00 0xbc 0x01>;
			phandle = <0xcf>;
			reg = <0x1f2cde80 0x40>;
			compatible = "sstar,timer";
		};

		arch_timer {
			interrupt-parent = <0x04>;
			interrupts = <0x01 0x0d 0x308 0x01 0x0e 0x308 0x01 0x0b 0x308 0x01 0x0a 0x308>;
			clock-frequency = <0x5b8d80>;
			compatible = "arm,cortex-a32-timer\0arm,armv8-timer";
		};

		timer8@0x1F2CDE40 {
			clocks = <0x10>;
			status = "ok";
			interrupts = <0x00 0xbb 0x01>;
			phandle = <0xce>;
			reg = <0x1f2cde40 0x40>;
			compatible = "sstar,timer";
		};

		bdma1 {
			clocks = <0xb2>;
			status = "ok";
			interrupts = <0x00 0x48 0x04>;
			reg = <0x1f200480 0x80>;
			compatible = "sstar,bdma1";
		};

		timer10@0x1F2CDEC0 {
			clocks = <0x10>;
			status = "ok";
			interrupts = <0x00 0xbd 0x01>;
			phandle = <0xd0>;
			reg = <0x1f2cdec0 0x40>;
			compatible = "sstar,timer";
		};

		ive@0x1F2A3C00 {
			clocks = <0x6e>;
			status = "ok";
			interrupts = <0x00 0x57 0x04>;
			phandle = <0xee>;
			reg = <0x1f2a3c00 0x100 0x1f2a3e00 0x100 0x1f2a4000 0x100>;
			compatible = "sstar,infinity-ive";
		};

		pwm@0x1F2034C0 {
			clocks = <0x8e>;
			channel = <0x07>;
			status = "ok";
			interrupts = <0x00 0x5b 0x04>;
			phandle = <0xe7>;
			reg = <0x1f2034c0 0x37>;
			group = <0x01>;
			#pwm-cells = <0x03>;
			clk-select = <0x00>;
			compatible = "sstar,pwm";
		};
	};

	reserved-memory {
		#address-cells = <0x01>;
		ranges;
		#size-cells = <0x01>;

		cma0 {
			alignment = <0x1000>;
			reusable;
			size = <0x1000000>;
			linux,cma-default;
			compatible = "shared-dma-pool";
		};
	};
};
